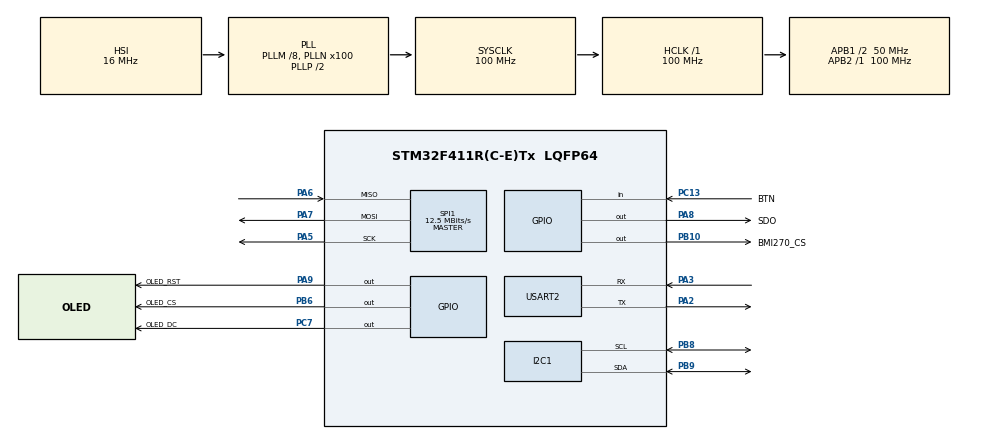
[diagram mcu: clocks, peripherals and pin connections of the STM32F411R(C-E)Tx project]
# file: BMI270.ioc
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Dma.I2C1_RX.1.Direction=DMA_PERIPH_TO_MEMORY
Dma.I2C1_RX.1.FIFOMode=DMA_FIFOMODE_DISABLE
Dma.I2C1_RX.1.Instance=DMA1_Stream0
Dma.I2C1_RX.1.MemDataAlignment=DMA_MDATAALIGN_BYTE
Dma.I2C1_RX.1.MemInc=DMA_MINC_ENABLE
Dma.I2C1_RX.1.Mode=DMA_NORMAL
Dma.I2C1_RX.1.PeriphDataAlignment=DMA_PDATAALIGN_BYTE
Dma.I2C1_RX.1.PeriphInc=DMA_PINC_DISABLE
Dma.I2C1_RX.1.Priority=DMA_PRIORITY_LOW
Dma.I2C1_TX.0.Direction=DMA_MEMORY_TO_PERIPH
Dma.I2C1_TX.0.FIFOMode=DMA_FIFOMODE_DISABLE
Dma.I2C1_TX.0.Instance=DMA1_Stream1
Dma.I2C1_TX.0.MemDataAlignment=DMA_MDATAALIGN_BYTE
Dma.I2C1_TX.0.MemInc=DMA_MINC_ENABLE
Dma.I2C1_TX.0.Mode=DMA_NORMAL
Dma.I2C1_TX.0.PeriphDataAlignment=DMA_PDATAALIGN_BYTE
Dma.I2C1_TX.0.PeriphInc=DMA_PINC_DISABLE
Dma.I2C1_TX.0.Priority=DMA_PRIORITY_LOW
Dma.Request0=I2C1_TX
Dma.Request1=I2C1_RX
I2C1.I2C_Mode=I2C_Fast
Mcu.Family=STM32F4
Mcu.Name=STM32F411R(C-E)Tx
Mcu.Package=LQFP64
NVIC.DMA1_Stream0_IRQn=true\:0\:0\:false\:false\:true\:false\:true\:true
NVIC.DMA1_Stream1_IRQn=true\:0\:0\:false\:false\:true\:false\:true\:true
NVIC.PriorityGroup=NVIC_PRIORITYGROUP_4
NVIC.RTC_WKUP_IRQn=true\:0\:0\:false\:false\:true\:true\:true\:true
PA13.Mode=Serial_Wire
PA13.Signal=SYS_JTMS-SWDIO
PA14.Mode=Serial_Wire
PA14.Signal=SYS_JTCK-SWCLK
PA2.Mode=Asynchronous
PA2.Signal=USART2_TX
PA3.Mode=Asynchronous
PA3.Signal=USART2_RX
PA5.Mode=Full_Duplex_Master
PA5.Signal=SPI1_SCK
PA6.Mode=Full_Duplex_Master
PA6.Signal=SPI1_MISO
PA7.Mode=Full_Duplex_Master
PA7.Signal=SPI1_MOSI
PA8.GPIO_Label=SDO
PA8.Signal=GPIO_Output
PA9.GPIO_Label=OLED_RST
PA9.Signal=GPIO_Output
PB10.GPIO_Label=BMI270_CS
PB10.Signal=GPIO_Output
PB6.GPIO_Label=OLED_CS
PB6.Signal=GPIO_Output
PB8.GPIO_Pu=GPIO_NOPULL
PB8.Mode=I2C
PB8.Signal=I2C1_SCL
PB9.GPIO_Pu=GPIO_NOPULL
PB9.Mode=I2C
PB9.Signal=I2C1_SDA
PC13-ANTI_TAMP.GPIO_Label=BTN
PC13-ANTI_TAMP.GPIO_PuPd=GPIO_PULLUP
PC13-ANTI_TAMP.Signal=GPIO_Input
PC14-OSC32_IN.Mode=LSE-External-Oscillator
PC14-OSC32_IN.Signal=RCC_OSC32_IN
PC15-OSC32_OUT.Mode=LSE-External-Oscillator
PC15-OSC32_OUT.Signal=RCC_OSC32_OUT
PC7.GPIO_Label=OLED_DC
PC7.Signal=GPIO_Output
ProjectManager.HeapSize=0x200
ProjectManager.StackSize=0x400
ProjectManager.TargetToolchain=STM32CubeIDE
RCC.48MHZClocksFreq_Value=50000000
RCC.AHBFreq_Value=100000000
RCC.APB1CLKDivider=RCC_HCLK_DIV2
RCC.APB1Freq_Value=50000000
RCC.APB1TimFreq_Value=100000000
RCC.APB2Freq_Value=100000000
RCC.APB2TimFreq_Value=100000000
RCC.CortexFreq_Value=100000000
RCC.HCLKFreq_Value=100000000
RCC.HSE_VALUE=25000000
RCC.HSI_VALUE=16000000
RCC.PLLM=8
RCC.PLLN=100
RCC.RCC_RTC_Clock_Source=RCC_RTCCLKSOURCE_LSE
RCC.RCC_RTC_Clock_SourceVirtual=RCC_RTCCLKSOURCE_LSE
RCC.SYSCLKFreq_VALUE=100000000
RCC.SYSCLKSource=RCC_SYSCLKSOURCE_PLLCLK
RCC.VCOOutputFreq_Value=200000000
RTC.WakeUpClock=RTC_WAKEUPCLOCK_RTCCLK_DIV16
RTC.WakeUpCounter=0
SPI1.BaudRatePrescaler=SPI_BAUDRATEPRESCALER_8
SPI1.CLKPhase=SPI_PHASE_2EDGE
SPI1.CLKPolarity=SPI_POLARITY_LOW
SPI1.CalculateBaudRate=12.5 MBits/s
SPI1.Direction=SPI_DIRECTION_2LINES
SPI1.Mode=SPI_MODE_MASTER
SPI1.VirtualType=VM_MASTER
USART2.VirtualMode=VM_ASYNC
VP_RTC_VS_RTC_Activate.Mode=RTC_Enabled
VP_RTC_VS_RTC_WakeUp_intern.Mode=WakeUp
VP_TIM5_VS_ClockSourceINT.Mode=Internal
board=custom

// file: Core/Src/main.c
/* USER CODE BEGIN Header */
/**
  ******************************************************************************
  * @file           : main.c
  * @brief          : Main program body
  ******************************************************************************
  * @attention
  *
  * Copyright (c) 2026 STMicroelectronics.
  * All rights reserved.
  *
  * This software is licensed under terms that can be found in the LICENSE file
  * in the root directory of this software component.
  * If no LICENSE file comes with this software, it is provided AS-IS.
  *
  ******************************************************************************
  */
/* USER CODE END Header */
#include "main.h"
#include "dma.h"
#include "i2c.h"
#include "rtc.h"
#include "spi.h"
#include "tim.h"
#include "usart.h"
#include "gpio.h"

/* USER CODE BEGIN Includes */
#include <stdio.h>
/* USER CODE END Includes */

/* USER CODE BEGIN PV */
uint8_t Buffer[25] = {0};
uint8_t temp[50];
uint8_t Space[] = " -- ";
uint8_t NewLine[] = "\r\n";
uint8_t StartMSG[] = "Starting I2C Scanning: \r\n";
uint8_t EndMSG[] = "\r\n ------ Done! ----- \r\n\r\n";
uint8_t i2c_address;

uint8_t bmi270_Config_File[8192] = {
    0xc8, 0x2e, 0x00, 0x2e, 0x80, 0x2e, 0x3d, 0xb1, 0xc8, 0x2e, 0x00, 0x2e, 0x80, 0x2e, 0x91, 0x03, 0x80, 0x2e, 0xbc,
    0xb0, 0x80, 0x2e, 0xa3, 0x03, 0xc8, 0x2e, 0x00, 0x2e, 0x80, 0x2e, 0x00, 0xb0, 0x50, 0x30, 0x21, 0x2e, 0x59, 0xf5,
    0x10, 0x30, 0x21, 0x2e, 0x6a, 0xf5, 0x80, 0x2e, 0x3b, 0x03, 0x00, 0x00, 0x00, 0x00, 0x08, 0x19, 0x01, 0x00, 0x22,
    0x00, 0x75, 0x00, 0x00, 0x10, 0x00, 0x10, 0xd1, 0x00, 0xb3, 0x43, 0x80, 0x2e, 0x00, 0xc1, 0x80, 0x2e, 0x00, 0xc1,
    0x80, 0x2e, 0x00, 0xc1, 0x80, 0x2e, 0x00, 0xc1, 0x80, 0x2e, 0x00, 0xc1, 0x80, 0x2e, 0x00, 0xc1, 0x80, 0x2e, 0x00,
    0xc1, 0x80, 0x2e, 0x00, 0xc1, 0x80, 0x2e, 0x00, 0xc1, 0x80, 0x2e, 0x00, 0xc1, 0x80, 0x2e, 0x00, 0xc1, 0x80, 0x2e,
    0x00, 0xc1, 0x80, 0x2e, 0x00, 0xc1, 0x80, 0x2e, 0x00, 0xc1, 0x80, 0x2e, 0x00, 0xc1, 0x80, 0x2e, 0x00, 0xc1, 0x80,
    0x2e, 0x00, 0xc1, 0x80, 0x2e, 0x00, 0xc1, 0x80, 0x2e, 0x00, 0xc1, 0x80, 0x2e, 0x00, 0xc1, 0x80, 0x2e, 0x00, 0xc1,
    0x80, 0x2e, 0x00, 0xc1, 0x80, 0x2e, 0x00, 0xc1, 0x80, 0x2e, 0x00, 0xc1, 0x80, 0x2e, 0x00, 0xc1, 0x80, 0x2e, 0x00,
    0xc1, 0x80, 0x2e, 0x00, 0xc1, 0x80, 0x2e, 0x00, 0xc1, 0x80, 0x2e, 0x00, 0xc1, 0x80, 0x2e, 0x00, 0xc1, 0x80, 0x2e,
    0x00, 0xc1, 0x80, 0x2e, 0x00, 0xc1, 0x80, 0x2e, 0x00, 0xc1, 0x80, 0x2e, 0x00, 0xc1, 0x80, 0x2e, 0x00, 0xc1, 0x80,
    0x2e, 0x00, 0xc1, 0x80, 0x2e, 0x00, 0xc1, 0x80, 0x2e, 0x00, 0xc1, 0x80, 0x2e, 0x00, 0xc1, 0x80, 0x2e, 0x00, 0xc1,
    0x80, 0x2e, 0x00, 0xc1, 0x80, 0x2e, 0x00, 0xc1, 0xe0, 0x5f, 0x00, 0x00, 0x00, 0x00, 0x01, 0x00, 0x00, 0x00, 0x00,
    0x00, 0x00, 0x00, 0x00, 0x00, 0x00, 0x00, 0x92, 0x00, 0x00, 0x00, 0x00, 0x00, 0x00, 0x00, 0x00, 0x00, 0x00, 0x00,
    0x00, 0x00, 0x00, 0x00, 0x00, 0x00, 0x08, 0x19, 0x00, 0x00, 0x88, 0x00, 0x00, 0x00, 0x00, 0x00, 0x00, 0x00, 0x05,
    0xe0, 0xaa, 0x38, 0x05, 0xe0, 0x90, 0x30, 0xfa, 0x00, 0x96, 0x00, 0x4b, 0x09, 0x11, 0x00, 0x11, 0x00, 0x02, 0x00,
    0x2d, 0x01, 0xd4, 0x7b, 0x3b, 0x01, 0xdb, 0x7a, 0x04, 0x00, 0x3f, 0x7b, 0xcd, 0x6c, 0xc3, 0x04, 0x85, 0x09, 0xc3,
    0x04, 0xec, 0xe6, 0x0c, 0x46, 0x01, 0x00, 0x27, 0x00, 0x19, 0x00, 0x96, 0x00, 0xa0, 0x00, 0x01, 0x00, 0x0c, 0x00,
    0xf0, 0x3c, 0x00, 0x01, 0x01, 0x00, 0x03, 0x00, 0x01, 0x00, 0x0e, 0x00, 0x00, 0x00, 0x32, 0x00, 0x05, 0x00, 0xee,
    0x06, 0x04, 0x00, 0xc8, 0x00, 0x00, 0x00, 0x04, 0x00, 0xa8, 0x05, 0xee, 0x06, 0x00, 0x04, 0xbc, 0x02, 0xb3, 0x00,
    0x85, 0x07, 0x00, 0x00, 0x00, 0x00, 0x00, 0x00, 0x00, 0x00, 0x00, 0x00, 0x00, 0x00, 0x00, 0x00, 0x00, 0x00, 0x00,
    0x00, 0x00, 0x00, 0xb4, 0x00, 0x01, 0x00, 0xb9, 0x00, 0x01, 0x00, 0x98, 0x00, 0x00, 0x00, 0x00, 0x00, 0x00, 0x00,
    0x00, 0x00, 0x01, 0x00, 0x80, 0x00, 0x04, 0x00, 0x00, 0x00, 0x00, 0x00, 0x00, 0x00, 0x00, 0x00, 0x00, 0x00, 0x00,
    0x00, 0x00, 0x00, 0x00, 0x00, 0x00, 0x00, 0x00, 0x00, 0x00, 0x00, 0x00, 0x00, 0x00, 0x00, 0x00, 0x00, 0x00, 0x00,
    0x00, 0x00, 0x00, 0x00, 0x00, 0x00, 0x00, 0x00, 0x00, 0x00, 0x00, 0x00, 0x00, 0x00, 0x00, 0x00, 0x00, 0x00, 0x00,
    0x00, 0x00, 0x00, 0x00, 0x00, 0x00, 0x00, 0x00, 0x00, 0x00, 0x00, 0x00, 0x00, 0x00, 0x00, 0x00, 0x00, 0x00, 0x00,
    0x00, 0x00, 0x00, 0x00, 0x00, 0x00, 0x00, 0x00, 0x00, 0x00, 0x00, 0x00, 0x80, 0x2e, 0x00, 0xc1, 0xfd, 0x2d, 0xde,
    0x00, 0xeb, 0x00, 0xda, 0x00, 0x00, 0x0c, 0xff, 0x0f, 0x00, 0x04, 0xc0, 0x00, 0x5b, 0xf5, 0xc9, 0x01, 0x1e, 0xf2,
    0x80, 0x00, 0x3f, 0xff, 0x19, 0xf4, 0x58, 0xf5, 0x66, 0xf5, 0x64, 0xf5, 0xc0, 0xf1, 0xf0, 0x00, 0xe0, 0x00, 0xcd,
    0x01, 0xd3, 0x01, 0xdb, 0x01, 0xff, 0x7f, 0xff, 0x01, 0xe4, 0x00, 0x74, 0xf7, 0xf3, 0x00, 0xfa, 0x00, 0xff, 0x3f,
    0xca, 0x03, 0x6c, 0x38, 0x56, 0xfe, 0x44, 0xfd, 0xbc, 0x02, 0xf9, 0x06, 0x00, 0xfc, 0x12, 0x02, 0xae, 0x01, 0x58,
    0xfa, 0x9a, 0xfd, 0x77, 0x05, 0xbb, 0x02, 0x96, 0x01, 0x95, 0x01, 0x7f, 0x01, 0x82, 0x01, 0x89, 0x01, 0x87, 0x01,
    0x88, 0x01, 0x8a, 0x01, 0x8c, 0x01, 0x8f, 0x01, 0x8d, 0x01, 0x92, 0x01, 0x91, 0x01, 0xdd, 0x00, 0x9f, 0x01, 0x7e,
    0x01, 0xdb, 0x00, 0xb6, 0x01, 0x70, 0x69, 0x26, 0xd3, 0x9c, 0x07, 0x1f, 0x05, 0x9d, 0x00, 0x00, 0x08, 0xbc, 0x05,
    0x37, 0xfa, 0xa2, 0x01, 0xaa, 0x01, 0xa1, 0x01, 0xa8, 0x01, 0xa0, 0x01, 0xa8, 0x05, 0xb4, 0x01, 0xb4, 0x01, 0xce,
    0x00, 0xd0, 0x00, 0xfc, 0x00, 0xc5, 0x01, 0xff, 0xfb, 0xb1, 0x00, 0x00, 0x38, 0x00, 0x30, 0xfd, 0xf5, 0xfc, 0xf5,
    0xcd, 0x01, 0xa0, 0x00, 0x5f, 0xff, 0x00, 0x40, 0xff, 0x00, 0x00, 0x80, 0x6d, 0x0f, 0xeb, 0x00, 0x7f, 0xff, 0xc2,
    0xf5, 0x68, 0xf7, 0xb3, 0xf1, 0x67, 0x0f, 0x5b, 0x0f, 0x61, 0x0f, 0x80, 0x0f, 0x58, 0xf7, 0x5b, 0xf7, 0x83, 0x0f,
    0x86, 0x00, 0x72, 0x0f, 0x85, 0x0f, 0xc6, 0xf1, 0x7f, 0x0f, 0x6c, 0xf7, 0x00, 0xe0, 0x00, 0xff, 0xd1, 0xf5, 0x87,
    0x0f, 0x8a, 0x0f, 0xff, 0x03, 0xf0, 0x3f, 0x8b, 0x00, 0x8e, 0x00, 0x90, 0x00, 0xb9, 0x00, 0x2d, 0xf5, 0xca, 0xf5,
    0xcb, 0x01, 0x20, 0xf2, 0x00, 0x00, 0x00, 0x00, 0x00, 0x00, 0x00, 0x00, 0x00, 0x00, 0x00, 0x00, 0x00, 0x00, 0x00,
    0x00, 0x00, 0x00, 0x00, 0x00, 0x00, 0x00, 0x00, 0x00, 0x00, 0x00, 0x00, 0x00, 0x00, 0x00, 0x00, 0x00, 0x00, 0x00,
    0x00, 0x00, 0x00, 0x00, 0x00, 0x00, 0x00, 0x00, 0x00, 0x00, 0x00, 0x00, 0x00, 0x00, 0x00, 0x00, 0x00, 0x00, 0x00,
    0x00, 0x00, 0x00, 0x00, 0x00, 0x00, 0x00, 0x00, 0x00, 0x00, 0x00, 0x00, 0x00, 0x00, 0x00, 0x00, 0x00, 0x00, 0x00,
    0x00, 0x00, 0x00, 0x00, 0x00, 0x00, 0x00, 0x00, 0x00, 0x00, 0x00, 0x00, 0x00, 0x00, 0x00, 0x00, 0x00, 0x00, 0x00,
    0x00, 0x00, 0x00, 0x00, 0x00, 0x00, 0x00, 0x00, 0x00, 0x00, 0x00, 0x00, 0x00, 0x00, 0x00, 0x00, 0x00, 0x00, 0x00,
    0x00, 0x00, 0x00, 0x00, 0x00, 0x00, 0x00, 0x00, 0x00, 0x00, 0x00, 0x00, 0x00, 0x00, 0x00, 0x00, 0x00, 0x00, 0x00,
    0x00, 0x00, 0x00, 0x00, 0x00, 0x00, 0x00, 0x00, 0x00, 0x00, 0x00, 0x00, 0x00, 0x00, 0x00, 0x00, 0x00, 0x00, 0x00,
    0x00, 0x00, 0x00, 0x00, 0x00, 0x00, 0x00, 0x00, 0x00, 0x00, 0x00, 0x00, 0x00, 0x00, 0x00, 0x00, 0x00, 0x00, 0x00,
    0x00, 0x00, 0x00, 0x00, 0x00, 0x00, 0x00, 0x00, 0x00, 0x00, 0x00, 0x00, 0x00, 0x00, 0x00, 0x00, 0x00, 0x00, 0x00,
    0x00, 0x00, 0x00, 0x00, 0x00, 0x00, 0x00, 0x00, 0x00, 0x00, 0x00, 0x00, 0x00, 0x00, 0x00, 0x00, 0x00, 0x00, 0x00,
    0x00, 0x00, 0x00, 0x00, 0x00, 0x00, 0x00, 0x00, 0x00, 0x00, 0x00, 0x00, 0x00, 0x00, 0x00, 0x30, 0x50, 0x98, 0x2e,
    0xd7, 0x0e, 0x50, 0x32, 0x98, 0x2e, 0xfa, 0x03, 0x00, 0x30, 0xf0, 0x7f, 0x00, 0x2e, 0x00, 0x2e, 0xd0, 0x2e, 0x00,
    0x2e, 0x01, 0x80, 0x08, 0xa2, 0xfb, 0x2f, 0x98, 0x2e, 0xba, 0x03, 0x21, 0x2e, 0x19, 0x00, 0x01, 0x2e, 0xee, 0x00,
    0x00, 0xb2, 0x07, 0x2f, 0x01, 0x2e, 0x19, 0x00, 0x00, 0xb2, 0x03, 0x2f, 0x01, 0x50, 0x03, 0x52, 0x98, 0x2e, 0x07,
    0xcc, 0x01, 0x2e, 0xdd, 0x00, 0x00, 0xb2, 0x27, 0x2f, 0x05, 0x2e, 0x8a, 0x00, 0x05, 0x52, 0x98, 0x2e, 0xc7, 0xc1,
    0x03, 0x2e, 0xe9, 0x00, 0x40, 0xb2, 0xf0, 0x7f, 0x08, 0x2f, 0x01, 0x2e, 0x19, 0x00, 0x00, 0xb2, 0x04, 0x2f, 0x00,
    0x30, 0x21, 0x2e, 0xe9, 0x00, 0x98, 0x2e, 0xb4, 0xb1, 0x01, 0x2e, 0x18, 0x00, 0x00, 0xb2, 0x10, 0x2f, 0x05, 0x50,
    0x98, 0x2e, 0x4d, 0xc3, 0x05, 0x50, 0x98, 0x2e, 0x5a, 0xc7, 0x98, 0x2e, 0xf9, 0xb4, 0x98, 0x2e, 0x54, 0xb2, 0x98,
    0x2e, 0x67, 0xb6, 0x98, 0x2e, 0x17, 0xb2, 0x10, 0x30, 0x21, 0x2e, 0x77, 0x00, 0x01, 0x2e, 0xef, 0x00, 0x00, 0xb2,
    0x04, 0x2f, 0x98, 0x2e, 0x7a, 0xb7, 0x00, 0x30, 0x21, 0x2e, 0xef, 0x00, 0x01, 0x2e, 0xd4, 0x00, 0x04, 0xae, 0x0b,
    0x2f, 0x01, 0x2e, 0xdd, 0x00, 0x00, 0xb2, 0x07, 0x2f, 0x05, 0x52, 0x98, 0x2e, 0x8e, 0x0e, 0x00, 0xb2, 0x02, 0x2f,
    0x10, 0x30, 0x21, 0x2e, 0x7d, 0x00, 0x01, 0x2e, 0x7d, 0x00, 0x00, 0x90, 0x90, 0x2e, 0xf1, 0x02, 0x01, 0x2e, 0xd7,
    0x00, 0x00, 0xb2, 0x04, 0x2f, 0x98, 0x2e, 0x2f, 0x0e, 0x00, 0x30, 0x21, 0x2e, 0x7b, 0x00, 0x01, 0x2e, 0x7b, 0x00,
    0x00, 0xb2, 0x12, 0x2f, 0x01, 0x2e, 0xd4, 0x00, 0x00, 0x90, 0x02, 0x2f, 0x98, 0x2e, 0x1f, 0x0e, 0x09, 0x2d, 0x98,
    0x2e, 0x81, 0x0d, 0x01, 0x2e, 0xd4, 0x00, 0x04, 0x90, 0x02, 0x2f, 0x50, 0x32, 0x98, 0x2e, 0xfa, 0x03, 0x00, 0x30,
    0x21, 0x2e, 0x7b, 0x00, 0x01, 0x2e, 0x7c, 0x00, 0x00, 0xb2, 0x90, 0x2e, 0x09, 0x03, 0x01, 0x2e, 0x7c, 0x00, 0x01,
    0x31, 0x01, 0x08, 0x00, 0xb2, 0x04, 0x2f, 0x98, 0x2e, 0x47, 0xcb, 0x10, 0x30, 0x21, 0x2e, 0x77, 0x00, 0x81, 0x30,
    0x01, 0x2e, 0x7c, 0x00, 0x01, 0x08, 0x00, 0xb2, 0x61, 0x2f, 0x03, 0x2e, 0x89, 0x00, 0x01, 0x2e, 0xd4, 0x00, 0x98,
    0xbc, 0x98, 0xb8, 0x05, 0xb2, 0x0f, 0x58, 0x23, 0x2f, 0x07, 0x90, 0x09, 0x54, 0x00, 0x30, 0x37, 0x2f, 0x15, 0x41,
    0x04, 0x41, 0xdc, 0xbe, 0x44, 0xbe, 0xdc, 0xba, 0x2c, 0x01, 0x61, 0x00, 0x0f, 0x56, 0x4a, 0x0f, 0x0c, 0x2f, 0xd1,
    0x42, 0x94, 0xb8, 0xc1, 0x42, 0x11, 0x30, 0x05, 0x2e, 0x6a, 0xf7, 0x2c, 0xbd, 0x2f, 0xb9, 0x80, 0xb2, 0x08, 0x22,
    0x98, 0x2e, 0xc3, 0xb7, 0x21, 0x2d, 0x61, 0x30, 0x23, 0x2e, 0xd4, 0x00, 0x98, 0x2e, 0xc3, 0xb7, 0x00, 0x30, 0x21,
    0x2e, 0x5a, 0xf5, 0x18, 0x2d, 0xe1, 0x7f, 0x50, 0x30, 0x98, 0x2e, 0xfa, 0x03, 0x0f, 0x52, 0x07, 0x50, 0x50, 0x42,
    0x70, 0x30, 0x0d, 0x54, 0x42, 0x42, 0x7e, 0x82, 0xe2, 0x6f, 0x80, 0xb2, 0x42, 0x42, 0x05, 0x2f, 0x21, 0x2e, 0xd4,
    0x00, 0x10, 0x30, 0x98, 0x2e, 0xc3, 0xb7, 0x03, 0x2d, 0x60, 0x30, 0x21, 0x2e, 0xd4, 0x00, 0x01, 0x2e, 0xd4, 0x00,
    0x06, 0x90, 0x18, 0x2f, 0x01, 0x2e, 0x76, 0x00, 0x0b, 0x54, 0x07, 0x52, 0xe0, 0x7f, 0x98, 0x2e, 0x7a, 0xc1, 0xe1,
    0x6f, 0x08, 0x1a, 0x40, 0x30, 0x08, 0x2f, 0x21, 0x2e, 0xd4, 0x00, 0x20, 0x30, 0x98, 0x2e, 0xaf, 0xb7, 0x50, 0x32,
    0x98, 0x2e, 0xfa, 0x03, 0x05, 0x2d, 0x98, 0x2e, 0x38, 0x0e, 0x00, 0x30, 0x21, 0x2e, 0xd4, 0x00, 0x00, 0x30, 0x21,
    0x2e, 0x7c, 0x00, 0x18, 0x2d, 0x01, 0x2e, 0xd4, 0x00, 0x03, 0xaa, 0x01, 0x2f, 0x98, 0x2e, 0x45, 0x0e, 0x01, 0x2e,
    0xd4, 0x00, 0x3f, 0x80, 0x03, 0xa2, 0x01, 0x2f, 0x00, 0x2e, 0x02, 0x2d, 0x98, 0x2e, 0x5b, 0x0e, 0x30, 0x30, 0x98,
    0x2e, 0xce, 0xb7, 0x00, 0x30, 0x21, 0x2e, 0x7d, 0x00, 0x50, 0x32, 0x98, 0x2e, 0xfa, 0x03, 0x01, 0x2e, 0x77, 0x00,
    0x00, 0xb2, 0x24, 0x2f, 0x98, 0x2e, 0xf5, 0xcb, 0x03, 0x2e, 0xd5, 0x00, 0x11, 0x54, 0x01, 0x0a, 0xbc, 0x84, 0x83,
    0x86, 0x21, 0x2e, 0xc9, 0x01, 0xe0, 0x40, 0x13, 0x52, 0xc4, 0x40, 0x82, 0x40, 0xa8, 0xb9, 0x52, 0x42, 0x43, 0xbe,
    0x53, 0x42, 0x04, 0x0a, 0x50, 0x42, 0xe1, 0x7f, 0xf0, 0x31, 0x41, 0x40, 0xf2, 0x6f, 0x25, 0xbd, 0x08, 0x08, 0x02,
    0x0a, 0xd0, 0x7f, 0x98, 0x2e, 0xa8, 0xcf, 0x06, 0xbc, 0xd1, 0x6f, 0xe2, 0x6f, 0x08, 0x0a, 0x80, 0x42, 0x98, 0x2e,
    0x58, 0xb7, 0x00, 0x30, 0x21, 0x2e, 0xee, 0x00, 0x21, 0x2e, 0x77, 0x00, 0x21, 0x2e, 0xdd, 0x00, 0x80, 0x2e, 0xf4,
    0x01, 0x1a, 0x24, 0x22, 0x00, 0x80, 0x2e, 0xec, 0x01, 0x10, 0x50, 0xfb, 0x7f, 0x98, 0x2e, 0xf3, 0x03, 0x57, 0x50,
    0xfb, 0x6f, 0x01, 0x30, 0x71, 0x54, 0x11, 0x42, 0x42, 0x0e, 0xfc, 0x2f, 0xc0, 0x2e, 0x01, 0x42, 0xf0, 0x5f, 0x80,
    0x2e, 0x00, 0xc1, 0xfd, 0x2d, 0x01, 0x00, 0x00, 0x00, 0x00, 0x00, 0x00, 0x00, 0x00, 0x00, 0x00, 0x00, 0x9a, 0x01,
    0x34, 0x03, 0x00, 0x00, 0x00, 0x00, 0x00, 0x00, 0x00, 0x00, 0x00, 0x00, 0x00, 0x00, 0x00, 0x00, 0x00, 0x00, 0x00,
    0x00, 0x00, 0x00, 0x00, 0x00, 0x00, 0x00, 0x00, 0x00, 0x00, 0x00, 0x00, 0x00, 0x00, 0x00, 0x00, 0x00, 0x00, 0x00,
    0x00, 0x00, 0x00, 0x00, 0x00, 0x00, 0x00, 0x00, 0x00, 0x00, 0x00, 0x00, 0x00, 0x00, 0x00, 0x00, 0x00, 0x00, 0x00,
    0x00, 0x00, 0x00, 0x00, 0x00, 0x00, 0x00, 0x00, 0x00, 0x00, 0x00, 0x00, 0x00, 0x00, 0x00, 0x00, 0x00, 0x00, 0x00,
    0x00, 0x00, 0x00, 0x00, 0x00, 0x00, 0x00, 0x00, 0x00, 0x00, 0x00, 0x00, 0x00, 0x00, 0x00, 0x00, 0x00, 0x00, 0x00,
    0x00, 0x00, 0x00, 0x00, 0x00, 0x00, 0x00, 0x00, 0x00, 0x00, 0x00, 0x00, 0x00, 0x00, 0x00, 0x00, 0x00, 0x00, 0x00,
    0x00, 0x00, 0x20, 0x50, 0xe7, 0x7f, 0xf6, 0x7f, 0x06, 0x32, 0x0f, 0x2e, 0x61, 0xf5, 0xfe, 0x09, 0xc0, 0xb3, 0x04,
    0x2f, 0x17, 0x30, 0x2f, 0x2e, 0xef, 0x00, 0x2d, 0x2e, 0x61, 0xf5, 0xf6, 0x6f, 0xe7, 0x6f, 0xe0, 0x5f, 0xc8, 0x2e,
    0x20, 0x50, 0xe7, 0x7f, 0xf6, 0x7f, 0x46, 0x30, 0x0f, 0x2e, 0xa4, 0xf1, 0xbe, 0x09, 0x80, 0xb3, 0x06, 0x2f, 0x0d,
    0x2e, 0xd4, 0x00, 0x84, 0xaf, 0x02, 0x2f, 0x16, 0x30, 0x2d, 0x2e, 0x7b, 0x00, 0x86, 0x30, 0x2d, 0x2e, 0x60, 0xf5,
    0xf6, 0x6f, 0xe7, 0x6f, 0xe0, 0x5f, 0xc8, 0x2e, 0x01, 0x2e, 0x77, 0xf7, 0x09, 0xbc, 0x0f, 0xb8, 0x00, 0xb2, 0x10,
    0x50, 0xfb, 0x7f, 0x10, 0x30, 0x0b, 0x2f, 0x03, 0x2e, 0x8a, 0x00, 0x96, 0xbc, 0x9f, 0xb8, 0x40, 0xb2, 0x05, 0x2f,
    0x03, 0x2e, 0x68, 0xf7, 0x9e, 0xbc, 0x9f, 0xb8, 0x40, 0xb2, 0x07, 0x2f, 0x03, 0x2e, 0x7e, 0x00, 0x41, 0x90, 0x01,
    0x2f, 0x98, 0x2e, 0xdc, 0x03, 0x03, 0x2c, 0x00, 0x30, 0x21, 0x2e, 0x7e, 0x00, 0xfb, 0x6f, 0xf0, 0x5f, 0xb8, 0x2e,
    0x20, 0x50, 0xe0, 0x7f, 0xfb, 0x7f, 0x00, 0x2e, 0x27, 0x50, 0x98, 0x2e, 0x3b, 0xc8, 0x29, 0x50, 0x98, 0x2e, 0xa7,
    0xc8, 0x01, 0x50, 0x98, 0x2e, 0x55, 0xcc, 0xe1, 0x6f, 0x2b, 0x50, 0x98, 0x2e, 0xe0, 0xc9, 0xfb, 0x6f, 0x00, 0x30,
    0xe0, 0x5f, 0x21, 0x2e, 0x7e, 0x00, 0xb8, 0x2e, 0x73, 0x50, 0x01, 0x30, 0x57, 0x54, 0x11, 0x42, 0x42, 0x0e, 0xfc,
    0x2f, 0xb8, 0x2e, 0x21, 0x2e, 0x59, 0xf5, 0x10, 0x30, 0xc0, 0x2e, 0x21, 0x2e, 0x4a, 0xf1, 0x90, 0x50, 0xf7, 0x7f,
    0xe6, 0x7f, 0xd5, 0x7f, 0xc4, 0x7f, 0xb3, 0x7f, 0xa1, 0x7f, 0x90, 0x7f, 0x82, 0x7f, 0x7b, 0x7f, 0x98, 0x2e, 0x35,
    0xb7, 0x00, 0xb2, 0x90, 0x2e, 0x97, 0xb0, 0x03, 0x2e, 0x8f, 0x00, 0x07, 0x2e, 0x91, 0x00, 0x05, 0x2e, 0xb1, 0x00,
    0x3f, 0xba, 0x9f, 0xb8, 0x01, 0x2e, 0xb1, 0x00, 0xa3, 0xbd, 0x4c, 0x0a, 0x05, 0x2e, 0xb1, 0x00, 0x04, 0xbe, 0xbf,
    0xb9, 0xcb, 0x0a, 0x4f, 0xba, 0x22, 0xbd, 0x01, 0x2e, 0xb3, 0x00, 0xdc, 0x0a, 0x2f, 0xb9, 0x03, 0x2e, 0xb8, 0x00,
    0x0a, 0xbe, 0x9a, 0x0a, 0xcf, 0xb9, 0x9b, 0xbc, 0x01, 0x2e, 0x97, 0x00, 0x9f, 0xb8, 0x93, 0x0a, 0x0f, 0xbc, 0x91,
    0x0a, 0x0f, 0xb8, 0x90, 0x0a, 0x25, 0x2e, 0x18, 0x00, 0x05, 0x2e, 0xc1, 0xf5, 0x2e, 0xbd, 0x2e, 0xb9, 0x01, 0x2e,
    0x19, 0x00, 0x31, 0x30, 0x8a, 0x04, 0x00, 0x90, 0x07, 0x2f, 0x01, 0x2e, 0xd4, 0x00, 0x04, 0xa2, 0x03, 0x2f, 0x01,
    0x2e, 0x18, 0x00, 0x00, 0xb2, 0x0c, 0x2f, 0x19, 0x50, 0x05, 0x52, 0x98, 0x2e, 0x4d, 0xb7, 0x05, 0x2e, 0x78, 0x00,
    0x80, 0x90, 0x10, 0x30, 0x01, 0x2f, 0x21, 0x2e, 0x78, 0x00, 0x25, 0x2e, 0xdd, 0x00, 0x98, 0x2e, 0x3e, 0xb7, 0x00,
    0xb2, 0x02, 0x30, 0x01, 0x30, 0x04, 0x2f, 0x01, 0x2e, 0x19, 0x00, 0x00, 0xb2, 0x00, 0x2f, 0x21, 0x30, 0x01, 0x2e,
    0xea, 0x00, 0x08, 0x1a, 0x0e, 0x2f, 0x23, 0x2e, 0xea, 0x00, 0x33, 0x30, 0x1b, 0x50, 0x0b, 0x09, 0x01, 0x40, 0x17,
    0x56, 0x46, 0xbe, 0x4b, 0x08, 0x4c, 0x0a, 0x01, 0x42, 0x0a, 0x80, 0x15, 0x52, 0x01, 0x42, 0x00, 0x2e, 0x01, 0x2e,
    0x18, 0x00, 0x00, 0xb2, 0x1f, 0x2f, 0x03, 0x2e, 0xc0, 0xf5, 0xf0, 0x30, 0x48, 0x08, 0x47, 0xaa, 0x74, 0x30, 0x07,
    0x2e, 0x7a, 0x00, 0x61, 0x22, 0x4b, 0x1a, 0x05, 0x2f, 0x07, 0x2e, 0x66, 0xf5, 0xbf, 0xbd, 0xbf, 0xb9, 0xc0, 0x90,
    0x0b, 0x2f, 0x1d, 0x56, 0x2b, 0x30, 0xd2, 0x42, 0xdb, 0x42, 0x01, 0x04, 0xc2, 0x42, 0x04, 0xbd, 0xfe, 0x80, 0x81,
    0x84, 0x23, 0x2e, 0x7a, 0x00, 0x02, 0x42, 0x02, 0x32, 0x25, 0x2e, 0x62, 0xf5, 0x05, 0x2e, 0xd6, 0x00, 0x81, 0x84,
    0x25, 0x2e, 0xd6, 0x00, 0x02, 0x31, 0x25, 0x2e, 0x60, 0xf5, 0x05, 0x2e, 0x8a, 0x00, 0x0b, 0x50, 0x90, 0x08, 0x80,
    0xb2, 0x0b, 0x2f, 0x05, 0x2e, 0xca, 0xf5, 0xf0, 0x3e, 0x90, 0x08, 0x25, 0x2e, 0xca, 0xf5, 0x05, 0x2e, 0x59, 0xf5,
    0xe0, 0x3f, 0x90, 0x08, 0x25, 0x2e, 0x59, 0xf5, 0x90, 0x6f, 0xa1, 0x6f, 0xb3, 0x6f, 0xc4, 0x6f, 0xd5, 0x6f, 0xe6,
    0x6f, 0xf7, 0x6f, 0x7b, 0x6f, 0x82, 0x6f, 0x70, 0x5f, 0xc8, 0x2e, 0xc0, 0x50, 0x90, 0x7f, 0xe5, 0x7f, 0xd4, 0x7f,
    0xc3, 0x7f, 0xb1, 0x7f, 0xa2, 0x7f, 0x87, 0x7f, 0xf6, 0x7f, 0x7b, 0x7f, 0x00, 0x2e, 0x01, 0x2e, 0x60, 0xf5, 0x60,
    0x7f, 0x98, 0x2e, 0x35, 0xb7, 0x02, 0x30, 0x63, 0x6f, 0x15, 0x52, 0x50, 0x7f, 0x62, 0x7f, 0x5a, 0x2c, 0x02, 0x32,
    0x1a, 0x09, 0x00, 0xb3, 0x14, 0x2f, 0x00, 0xb2, 0x03, 0x2f, 0x09, 0x2e, 0x18, 0x00, 0x00, 0x91, 0x0c, 0x2f, 0x43,
    0x7f, 0x98, 0x2e, 0x97, 0xb7, 0x1f, 0x50, 0x02, 0x8a, 0x02, 0x32, 0x04, 0x30, 0x25, 0x2e, 0x64, 0xf5, 0x15, 0x52,
    0x50, 0x6f, 0x43, 0x6f, 0x44, 0x43, 0x25, 0x2e, 0x60, 0xf5, 0xd9, 0x08, 0xc0, 0xb2, 0x36, 0x2f, 0x98, 0x2e, 0x3e,
    0xb7, 0x00, 0xb2, 0x06, 0x2f, 0x01, 0x2e, 0x19, 0x00, 0x00, 0xb2, 0x02, 0x2f, 0x50, 0x6f, 0x00, 0x90, 0x0a, 0x2f,
    0x01, 0x2e, 0x79, 0x00, 0x00, 0x90, 0x19, 0x2f, 0x10, 0x30, 0x21, 0x2e, 0x79, 0x00, 0x00, 0x30, 0x98, 0x2e, 0xdc,
    0x03, 0x13, 0x2d, 0x01, 0x2e, 0xc3, 0xf5, 0x0c, 0xbc, 0x0f, 0xb8, 0x12, 0x30, 0x10, 0x04, 0x03, 0xb0, 0x26, 0x25,
    0x21, 0x50, 0x03, 0x52, 0x98, 0x2e, 0x4d, 0xb7, 0x10, 0x30, 0x21, 0x2e, 0xee, 0x00, 0x02, 0x30, 0x60, 0x7f, 0x25,
    0x2e, 0x79, 0x00, 0x60, 0x6f, 0x00, 0x90, 0x05, 0x2f, 0x00, 0x30, 0x21, 0x2e, 0xea, 0x00, 0x15, 0x50, 0x21, 0x2e,
    0x64, 0xf5, 0x15, 0x52, 0x23, 0x2e, 0x60, 0xf5, 0x02, 0x32, 0x50, 0x6f, 0x00, 0x90, 0x02, 0x2f, 0x03, 0x30, 0x27,
    0x2e, 0x78, 0x00, 0x07, 0x2e, 0x60, 0xf5, 0x1a, 0x09, 0x00, 0x91, 0xa3, 0x2f, 0x19, 0x09, 0x00, 0x91, 0xa0, 0x2f,
    0x90, 0x6f, 0xa2, 0x6f, 0xb1, 0x6f, 0xc3, 0x6f, 0xd4, 0x6f, 0xe5, 0x6f, 0x7b, 0x6f, 0xf6, 0x6f, 0x87, 0x6f, 0x40,
    0x5f, 0xc8, 0x2e, 0xc0, 0x50, 0xe7, 0x7f, 0xf6, 0x7f, 0x26, 0x30, 0x0f, 0x2e, 0x61, 0xf5, 0x2f, 0x2e, 0x7c, 0x00,
    0x0f, 0x2e, 0x7c, 0x00, 0xbe, 0x09, 0xa2, 0x7f, 0x80, 0x7f, 0x80, 0xb3, 0xd5, 0x7f, 0xc4, 0x7f, 0xb3, 0x7f, 0x91,
    0x7f, 0x7b, 0x7f, 0x0b, 0x2f, 0x23, 0x50, 0x1a, 0x25, 0x12, 0x40, 0x42, 0x7f, 0x74, 0x82, 0x12, 0x40, 0x52, 0x7f,
    0x00, 0x2e, 0x00, 0x40, 0x60, 0x7f, 0x98, 0x2e, 0x6a, 0xd6, 0x81, 0x30, 0x01, 0x2e, 0x7c, 0x00, 0x01, 0x08, 0x00,
    0xb2, 0x42, 0x2f, 0x03, 0x2e, 0x89, 0x00, 0x01, 0x2e, 0x89, 0x00, 0x97, 0xbc, 0x06, 0xbc, 0x9f, 0xb8, 0x0f, 0xb8,
    0x00, 0x90, 0x23, 0x2e, 0xd8, 0x00, 0x10, 0x30, 0x01, 0x30, 0x2a, 0x2f, 0x03, 0x2e, 0xd4, 0x00, 0x44, 0xb2, 0x05,
    0x2f, 0x47, 0xb2, 0x00, 0x30, 0x2d, 0x2f, 0x21, 0x2e, 0x7c, 0x00, 0x2b, 0x2d, 0x03, 0x2e, 0xfd, 0xf5, 0x9e, 0xbc,
    0x9f, 0xb8, 0x40, 0x90, 0x14, 0x2f, 0x03, 0x2e, 0xfc, 0xf5, 0x99, 0xbc, 0x9f, 0xb8, 0x40, 0x90, 0x0e, 0x2f, 0x03,
    0x2e, 0x49, 0xf1, 0x25, 0x54, 0x4a, 0x08, 0x40, 0x90, 0x08, 0x2f, 0x98, 0x2e, 0x35, 0xb7, 0x00, 0xb2, 0x10, 0x30,
    0x03, 0x2f, 0x50, 0x30, 0x21, 0x2e, 0xd4, 0x00, 0x10, 0x2d, 0x98, 0x2e, 0xaf, 0xb7, 0x00, 0x30, 0x21, 0x2e, 0x7c,
    0x00, 0x0a, 0x2d, 0x05, 0x2e, 0x69, 0xf7, 0x2d, 0xbd, 0x2f, 0xb9, 0x80, 0xb2, 0x01, 0x2f, 0x21, 0x2e, 0x7d, 0x00,
    0x23, 0x2e, 0x7c, 0x00, 0xe0, 0x31, 0x21, 0x2e, 0x61, 0xf5, 0xf6, 0x6f, 0xe7, 0x6f, 0x80, 0x6f, 0xa2, 0x6f, 0xb3,
    0x6f, 0xc4, 0x6f, 0xd5, 0x6f, 0x7b, 0x6f, 0x91, 0x6f, 0x40, 0x5f, 0xc8, 0x2e, 0x60, 0x51, 0x0a, 0x25, 0x36, 0x88,
    0xf4, 0x7f, 0xeb, 0x7f, 0x00, 0x32, 0x31, 0x52, 0x32, 0x30, 0x13, 0x30, 0x98, 0x2e, 0x15, 0xcb, 0x0a, 0x25, 0x33,
    0x84, 0xd2, 0x7f, 0x43, 0x30, 0x05, 0x50, 0x2d, 0x52, 0x98, 0x2e, 0x95, 0xc1, 0xd2, 0x6f, 0x27, 0x52, 0x98, 0x2e,
    0xd7, 0xc7, 0x2a, 0x25, 0xb0, 0x86, 0xc0, 0x7f, 0xd3, 0x7f, 0xaf, 0x84, 0x29, 0x50, 0xf1, 0x6f, 0x98, 0x2e, 0x4d,
    0xc8, 0x2a, 0x25, 0xae, 0x8a, 0xaa, 0x88, 0xf2, 0x6e, 0x2b, 0x50, 0xc1, 0x6f, 0xd3, 0x6f, 0xf4, 0x7f, 0x98, 0x2e,
    0xb6, 0xc8, 0xe0, 0x6e, 0x00, 0xb2, 0x32, 0x2f, 0x33, 0x54, 0x83, 0x86, 0xf1, 0x6f, 0xc3, 0x7f, 0x04, 0x30, 0x30,
    0x30, 0xf4, 0x7f, 0xd0, 0x7f, 0xb2, 0x7f, 0xe3, 0x30, 0xc5, 0x6f, 0x56, 0x40, 0x45, 0x41, 0x28, 0x08, 0x03, 0x14,
    0x0e, 0xb4, 0x08, 0xbc, 0x82, 0x40, 0x10, 0x0a, 0x2f, 0x54, 0x26, 0x05, 0x91, 0x7f, 0x44, 0x28, 0xa3, 0x7f, 0x98,
    0x2e, 0xd9, 0xc0, 0x08, 0xb9, 0x33, 0x30, 0x53, 0x09, 0xc1, 0x6f, 0xd3, 0x6f, 0xf4, 0x6f, 0x83, 0x17, 0x47, 0x40,
    0x6c, 0x15, 0xb2, 0x6f, 0xbe, 0x09, 0x75, 0x0b, 0x90, 0x42, 0x45, 0x42, 0x51, 0x0e, 0x32, 0xbc, 0x02, 0x89, 0xa1,
    0x6f, 0x7e, 0x86, 0xf4, 0x7f, 0xd0, 0x7f, 0xb2, 0x7f, 0x04, 0x30, 0x91, 0x6f, 0xd6, 0x2f, 0xeb, 0x6f, 0xa0, 0x5e,
    0xb8, 0x2e, 0x03, 0x2e, 0x97, 0x00, 0x1b, 0xbc, 0x60, 0x50, 0x9f, 0xbc, 0x0c, 0xb8, 0xf0, 0x7f, 0x40, 0xb2, 0xeb,
    0x7f, 0x2b, 0x2f, 0x03, 0x2e, 0x7f, 0x00, 0x41, 0x40, 0x01, 0x2e, 0xc8, 0x00, 0x01, 0x1a, 0x11, 0x2f, 0x37, 0x58,
    0x23, 0x2e, 0xc8, 0x00, 0x10, 0x41, 0xa0, 0x7f, 0x38, 0x81, 0x01, 0x41, 0xd0, 0x7f, 0xb1, 0x7f, 0x98, 0x2e, 0x64,
    0xcf, 0xd0, 0x6f, 0x07, 0x80, 0xa1, 0x6f, 0x11, 0x42, 0x00, 0x2e, 0xb1, 0x6f, 0x01, 0x42, 0x11, 0x30, 0x01, 0x2e,
    0xfc, 0x00, 0x00, 0xa8, 0x03, 0x30, 0xcb, 0x22, 0x4a, 0x25, 0x01, 0x2e, 0x7f, 0x00, 0x3c, 0x89, 0x35, 0x52, 0x05,
    0x54, 0x98, 0x2e, 0xc4, 0xce, 0xc1, 0x6f, 0xf0, 0x6f, 0x98, 0x2e, 0x95, 0xcf, 0x04, 0x2d, 0x01, 0x30, 0xf0, 0x6f,
    0x98, 0x2e, 0x95, 0xcf, 0xeb, 0x6f, 0xa0, 0x5f, 0xb8, 0x2e, 0x03, 0x2e, 0xb3, 0x00, 0x02, 0x32, 0xf0, 0x30, 0x03,
    0x31, 0x30, 0x50, 0x8a, 0x08, 0x08, 0x08, 0xcb, 0x08, 0xe0, 0x7f, 0x80, 0xb2, 0xf3, 0x7f, 0xdb, 0x7f, 0x25, 0x2f,
    0x03, 0x2e, 0xca, 0x00, 0x41, 0x90, 0x04, 0x2f, 0x01, 0x30, 0x23, 0x2e, 0xca, 0x00, 0x98, 0x2e, 0x3f, 0x03, 0xc0,
    0xb2, 0x05, 0x2f, 0x03, 0x2e, 0xda, 0x00, 0x00, 0x30, 0x41, 0x04, 0x23, 0x2e, 0xda, 0x00, 0x98, 0x2e, 0x92, 0xb2,
    0x10, 0x25, 0xf0, 0x6f, 0x00, 0xb2, 0x05, 0x2f, 0x01, 0x2e, 0xda, 0x00, 0x02, 0x30, 0x10, 0x04, 0x21, 0x2e, 0xda,
    0x00, 0x40, 0xb2, 0x01, 0x2f, 0x23, 0x2e, 0xc8, 0x01, 0xdb, 0x6f, 0xe0, 0x6f, 0xd0, 0x5f, 0x80, 0x2e, 0x95, 0xcf,
    0x01, 0x30, 0xe0, 0x6f, 0x98, 0x2e, 0x95, 0xcf, 0x11, 0x30, 0x23, 0x2e, 0xca, 0x00, 0xdb, 0x6f, 0xd0, 0x5f, 0xb8,
    0x2e, 0xd0, 0x50, 0x0a, 0x25, 0x33, 0x84, 0x55, 0x50, 0xd2, 0x7f, 0xe2, 0x7f, 0x03, 0x8c, 0xc0, 0x7f, 0xbb, 0x7f,
    0x00, 0x30, 0x05, 0x5a, 0x39, 0x54, 0x51, 0x41, 0xa5, 0x7f, 0x96, 0x7f, 0x80, 0x7f, 0x98, 0x2e, 0xd9, 0xc0, 0x05,
    0x30, 0xf5, 0x7f, 0x20, 0x25, 0x91, 0x6f, 0x3b, 0x58, 0x3d, 0x5c, 0x3b, 0x56, 0x98, 0x2e, 0x67, 0xcc, 0xc1, 0x6f,
    0xd5, 0x6f, 0x52, 0x40, 0x50, 0x43, 0xc1, 0x7f, 0xd5, 0x7f, 0x10, 0x25, 0x98, 0x2e, 0xfe, 0xc9, 0x10, 0x25, 0x98,
    0x2e, 0x74, 0xc0, 0x86, 0x6f, 0x30, 0x28, 0x92, 0x6f, 0x82, 0x8c, 0xa5, 0x6f, 0x6f, 0x52, 0x69, 0x0e, 0x39, 0x54,
    0xdb, 0x2f, 0x19, 0xa0, 0x15, 0x30, 0x03, 0x2f, 0x00, 0x30, 0x21, 0x2e, 0x81, 0x01, 0x0a, 0x2d, 0x01, 0x2e, 0x81,
    0x01, 0x05, 0x28, 0x42, 0x36, 0x21, 0x2e, 0x81, 0x01, 0x02, 0x0e, 0x01, 0x2f, 0x98, 0x2e, 0xf3, 0x03, 0x57, 0x50,
    0x12, 0x30, 0x01, 0x40, 0x98, 0x2e, 0xfe, 0xc9, 0x51, 0x6f, 0x0b, 0x5c, 0x8e, 0x0e, 0x3b, 0x6f, 0x57, 0x58, 0x02,
    0x30, 0x21, 0x2e, 0x95, 0x01, 0x45, 0x6f, 0x2a, 0x8d, 0xd2, 0x7f, 0xcb, 0x7f, 0x13, 0x2f, 0x02, 0x30, 0x3f, 0x50,
    0xd2, 0x7f, 0xa8, 0x0e, 0x0e, 0x2f, 0xc0, 0x6f, 0x53, 0x54, 0x02, 0x00, 0x51, 0x54, 0x42, 0x0e, 0x10, 0x30, 0x59,
    0x52, 0x02, 0x30, 0x01, 0x2f, 0x00, 0x2e, 0x03, 0x2d, 0x50, 0x42, 0x42, 0x42, 0x12, 0x30, 0xd2, 0x7f, 0x80, 0xb2,
    0x03, 0x2f, 0x00, 0x30, 0x21, 0x2e, 0x80, 0x01, 0x12, 0x2d, 0x01, 0x2e, 0xc9, 0x00, 0x02, 0x80, 0x05, 0x2e, 0x80,
    0x01, 0x11, 0x30, 0x91, 0x28, 0x00, 0x40, 0x25, 0x2e, 0x80, 0x01, 0x10, 0x0e, 0x05, 0x2f, 0x01, 0x2e, 0x7f, 0x01,
    0x01, 0x90, 0x01, 0x2f, 0x98, 0x2e, 0xf3, 0x03, 0x00, 0x2e, 0xa0, 0x41, 0x01, 0x90, 0xa6, 0x7f, 0x90, 0x2e, 0xe3,
    0xb4, 0x01, 0x2e, 0x95, 0x01, 0x00, 0xa8, 0x90, 0x2e, 0xe3, 0xb4, 0x5b, 0x54, 0x95, 0x80, 0x82, 0x40, 0x80, 0xb2,
    0x02, 0x40, 0x2d, 0x8c, 0x3f, 0x52, 0x96, 0x7f, 0x90, 0x2e, 0xc2, 0xb3, 0x29, 0x0e, 0x76, 0x2f, 0x01, 0x2e, 0xc9,
    0x00, 0x00, 0x40, 0x81, 0x28, 0x45, 0x52, 0xb3, 0x30, 0x98, 0x2e, 0x0f, 0xca, 0x5d, 0x54, 0x80, 0x7f, 0x00, 0x2e,
    0xa1, 0x40, 0x72, 0x7f, 0x82, 0x80, 0x82, 0x40, 0x60, 0x7f, 0x98, 0x2e, 0xfe, 0xc9, 0x10, 0x25, 0x98, 0x2e, 0x74,
    0xc0, 0x62, 0x6f, 0x05, 0x30, 0x87, 0x40, 0xc0, 0x91, 0x04, 0x30, 0x05, 0x2f, 0x05, 0x2e, 0x83, 0x01, 0x80, 0xb2,
    0x14, 0x30, 0x00, 0x2f, 0x04, 0x30, 0x05, 0x2e, 0xc9, 0x00, 0x73, 0x6f, 0x81, 0x40, 0xe2, 0x40, 0x69, 0x04, 0x11,
    0x0f, 0xe1, 0x40, 0x16, 0x30, 0xfe, 0x29, 0xcb, 0x40, 0x02, 0x2f, 0x83, 0x6f, 0x83, 0x0f, 0x22, 0x2f, 0x47, 0x56,
    0x13, 0x0f, 0x12, 0x30, 0x77, 0x2f, 0x49, 0x54, 0x42, 0x0e, 0x12, 0x30, 0x73, 0x2f, 0x00, 0x91, 0x0a, 0x2f, 0x01,
    0x2e, 0x8b, 0x01, 0x19, 0xa8, 0x02, 0x30, 0x6c, 0x2f, 0x63, 0x50, 0x00, 0x2e, 0x17, 0x42, 0x05, 0x42, 0x68, 0x2c,
    0x12, 0x30, 0x0b, 0x25, 0x08, 0x0f, 0x50, 0x30, 0x02, 0x2f, 0x21, 0x2e, 0x83, 0x01, 0x03, 0x2d, 0x40, 0x30, 0x21,
    0x2e, 0x83, 0x01, 0x2b, 0x2e, 0x85, 0x01, 0x5a, 0x2c, 0x12, 0x30, 0x00, 0x91, 0x2b, 0x25, 0x04, 0x2f, 0x63, 0x50,
    0x02, 0x30, 0x17, 0x42, 0x17, 0x2c, 0x02, 0x42, 0x98, 0x2e, 0xfe, 0xc9, 0x10, 0x25, 0x98, 0x2e, 0x74, 0xc0, 0x05,
    0x2e, 0xc9, 0x00, 0x81, 0x84, 0x5b, 0x30, 0x82, 0x40, 0x37, 0x2e, 0x83, 0x01, 0x02, 0x0e, 0x07, 0x2f, 0x5f, 0x52,
    0x40, 0x30, 0x62, 0x40, 0x41, 0x40, 0x91, 0x0e, 0x01, 0x2f, 0x21, 0x2e, 0x83, 0x01, 0x05, 0x30, 0x2b, 0x2e, 0x85,
    0x01, 0x12, 0x30, 0x36, 0x2c, 0x16, 0x30, 0x15, 0x25, 0x81, 0x7f, 0x98, 0x2e, 0xfe, 0xc9, 0x10, 0x25, 0x98, 0x2e,
    0x74, 0xc0, 0x19, 0xa2, 0x16, 0x30, 0x15, 0x2f, 0x05, 0x2e, 0x97, 0x01, 0x80, 0x6f, 0x82, 0x0e, 0x05, 0x2f, 0x01,
    0x2e, 0x86, 0x01, 0x06, 0x28, 0x21, 0x2e, 0x86, 0x01, 0x0b, 0x2d, 0x03, 0x2e, 0x87, 0x01, 0x5f, 0x54, 0x4e, 0x28,
    0x91, 0x42, 0x00, 0x2e, 0x82, 0x40, 0x90, 0x0e, 0x01, 0x2f, 0x21, 0x2e, 0x88, 0x01, 0x02, 0x30, 0x13, 0x2c, 0x05,
    0x30, 0xc0, 0x6f, 0x08, 0x1c, 0xa8, 0x0f, 0x16, 0x30, 0x05, 0x30, 0x5b, 0x50, 0x09, 0x2f, 0x02, 0x80, 0x2d, 0x2e,
    0x82, 0x01, 0x05, 0x42, 0x05, 0x80, 0x00, 0x2e, 0x02, 0x42, 0x3e, 0x80, 0x00, 0x2e, 0x06, 0x42, 0x02, 0x30, 0x90,
    0x6f, 0x3e, 0x88, 0x01, 0x40, 0x04, 0x41, 0x4c, 0x28, 0x01, 0x42, 0x07, 0x80, 0x10, 0x25, 0x24, 0x40, 0x00, 0x40,
    0x00, 0xa8, 0xf5, 0x22, 0x23, 0x29, 0x44, 0x42, 0x7a, 0x82, 0x7e, 0x88, 0x43, 0x40, 0x04, 0x41, 0x00, 0xab, 0xf5,
    0x23, 0xdf, 0x28, 0x43, 0x42, 0xd9, 0xa0, 0x14, 0x2f, 0x00, 0x90, 0x02, 0x2f, 0xd2, 0x6f, 0x81, 0xb2, 0x05, 0x2f,
    0x63, 0x54, 0x06, 0x28, 0x90, 0x42, 0x85, 0x42, 0x09, 0x2c, 0x02, 0x30, 0x5b, 0x50, 0x03, 0x80, 0x29, 0x2e, 0x7e,
    0x01, 0x2b, 0x2e, 0x82, 0x01, 0x05, 0x42, 0x12, 0x30, 0x2b, 0x2e, 0x83, 0x01, 0x45, 0x82, 0x00, 0x2e, 0x40, 0x40,
    0x7a, 0x82, 0x02, 0xa0, 0x08, 0x2f, 0x63, 0x50, 0x3b, 0x30, 0x15, 0x42, 0x05, 0x42, 0x37, 0x80, 0x37, 0x2e, 0x7e,
    0x01, 0x05, 0x42, 0x12, 0x30, 0x01, 0x2e, 0xc9, 0x00, 0x02, 0x8c, 0x40, 0x40, 0x84, 0x41, 0x7a, 0x8c, 0x04, 0x0f,
    0x03, 0x2f, 0x01, 0x2e, 0x8b, 0x01, 0x19, 0xa4, 0x04, 0x2f, 0x2b, 0x2e, 0x82, 0x01, 0x98, 0x2e, 0xf3, 0x03, 0x12,
    0x30, 0x81, 0x90, 0x61, 0x52, 0x08, 0x2f, 0x65, 0x42, 0x65, 0x42, 0x43, 0x80, 0x39, 0x84, 0x82, 0x88, 0x05, 0x42,
    0x45, 0x42, 0x85, 0x42, 0x05, 0x43, 0x00, 0x2e, 0x80, 0x41, 0x00, 0x90, 0x90, 0x2e, 0xe1, 0xb4, 0x65, 0x54, 0xc1,
    0x6f, 0x80, 0x40, 0x00, 0xb2, 0x43, 0x58, 0x69, 0x50, 0x44, 0x2f, 0x55, 0x5c, 0xb7, 0x87, 0x8c, 0x0f, 0x0d, 0x2e,
    0x96, 0x01, 0xc4, 0x40, 0x36, 0x2f, 0x41, 0x56, 0x8b, 0x0e, 0x2a, 0x2f, 0x0b, 0x52, 0xa1, 0x0e, 0x0a, 0x2f, 0x05,
    0x2e, 0x8f, 0x01, 0x14, 0x25, 0x98, 0x2e, 0xfe, 0xc9, 0x4b, 0x54, 0x02, 0x0f, 0x69, 0x50, 0x05, 0x30, 0x65, 0x54,
    0x15, 0x2f, 0x03, 0x2e, 0x8e, 0x01, 0x4d, 0x5c, 0x8e, 0x0f, 0x3a, 0x2f, 0x05, 0x2e, 0x8f, 0x01, 0x98, 0x2e, 0xfe,
    0xc9, 0x4f, 0x54, 0x82, 0x0f, 0x05, 0x30, 0x69, 0x50, 0x65, 0x54, 0x30, 0x2f, 0x6d, 0x52, 0x15, 0x30, 0x42, 0x8c,
    0x45, 0x42, 0x04, 0x30, 0x2b, 0x2c, 0x84, 0x43, 0x6b, 0x52, 0x42, 0x8c, 0x00, 0x2e, 0x85, 0x43, 0x15, 0x30, 0x24,
    0x2c, 0x45, 0x42, 0x8e, 0x0f, 0x20, 0x2f, 0x0d, 0x2e, 0x8e, 0x01, 0xb1, 0x0e, 0x1c, 0x2f, 0x23, 0x2e, 0x8e, 0x01,
    0x1a, 0x2d, 0x0e, 0x0e, 0x17, 0x2f, 0xa1, 0x0f, 0x15, 0x2f, 0x23, 0x2e, 0x8d, 0x01, 0x13, 0x2d, 0x98, 0x2e, 0x74,
    0xc0, 0x43, 0x54, 0xc2, 0x0e, 0x0a, 0x2f, 0x65, 0x50, 0x04, 0x80, 0x0b, 0x30, 0x06, 0x82, 0x0b, 0x42, 0x79, 0x80,
    0x41, 0x40, 0x12, 0x30, 0x25, 0x2e, 0x8c, 0x01, 0x01, 0x42, 0x05, 0x30, 0x69, 0x50, 0x65, 0x54, 0x84, 0x82, 0x43,
    0x84, 0xbe, 0x8c, 0x84, 0x40, 0x86, 0x41, 0x26, 0x29, 0x94, 0x42, 0xbe, 0x8e, 0xd5, 0x7f, 0x19, 0xa1, 0x43, 0x40,
    0x0b, 0x2e, 0x8c, 0x01, 0x84, 0x40, 0xc7, 0x41, 0x5d, 0x29, 0x27, 0x29, 0x45, 0x42, 0x84, 0x42, 0xc2, 0x7f, 0x01,
    0x2f, 0xc0, 0xb3, 0x1d, 0x2f, 0x05, 0x2e, 0x94, 0x01, 0x99, 0xa0, 0x01, 0x2f, 0x80, 0xb3, 0x13, 0x2f, 0x80, 0xb3,
    0x18, 0x2f, 0xc0, 0xb3, 0x16, 0x2f, 0x12, 0x40, 0x01, 0x40, 0x92, 0x7f, 0x98, 0x2e, 0x74, 0xc0, 0x92, 0x6f, 0x10,
    0x0f, 0x20, 0x30, 0x03, 0x2f, 0x10, 0x30, 0x21, 0x2e, 0x7e, 0x01, 0x0a, 0x2d, 0x21, 0x2e, 0x7e, 0x01, 0x07, 0x2d,
    0x20, 0x30, 0x21, 0x2e, 0x7e, 0x01, 0x03, 0x2d, 0x10, 0x30, 0x21, 0x2e, 0x7e, 0x01, 0xc2, 0x6f, 0x01, 0x2e, 0xc9,
    0x00, 0xbc, 0x84, 0x02, 0x80, 0x82, 0x40, 0x00, 0x40, 0x90, 0x0e, 0xd5, 0x6f, 0x02, 0x2f, 0x15, 0x30, 0x98, 0x2e,
    0xf3, 0x03, 0x41, 0x91, 0x05, 0x30, 0x07, 0x2f, 0x67, 0x50, 0x3d, 0x80, 0x2b, 0x2e, 0x8f, 0x01, 0x05, 0x42, 0x04,
    0x80, 0x00, 0x2e, 0x05, 0x42, 0x02, 0x2c, 0x00, 0x30, 0x00, 0x30, 0xa2, 0x6f, 0x98, 0x8a, 0x86, 0x40, 0x80, 0xa7,
    0x05, 0x2f, 0x98, 0x2e, 0xf3, 0x03, 0xc0, 0x30, 0x21, 0x2e, 0x95, 0x01, 0x06, 0x25, 0x1a, 0x25, 0xe2, 0x6f, 0x76,
    0x82, 0x96, 0x40, 0x56, 0x43, 0x51, 0x0e, 0xfb, 0x2f, 0xbb, 0x6f, 0x30, 0x5f, 0xb8, 0x2e, 0x01, 0x2e, 0xb8, 0x00,
    0x01, 0x31, 0x41, 0x08, 0x40, 0xb2, 0x20, 0x50, 0xf2, 0x30, 0x02, 0x08, 0xfb, 0x7f, 0x01, 0x30, 0x10, 0x2f, 0x05,
    0x2e, 0xcc, 0x00, 0x81, 0x90, 0xe0, 0x7f, 0x03, 0x2f, 0x23, 0x2e, 0xcc, 0x00, 0x98, 0x2e, 0x55, 0xb6, 0x98, 0x2e,
    0x1d, 0xb5, 0x10, 0x25, 0xfb, 0x6f, 0xe0, 0x6f, 0xe0, 0x5f, 0x80, 0x2e, 0x95, 0xcf, 0x98, 0x2e, 0x95, 0xcf, 0x10,
    0x30, 0x21, 0x2e, 0xcc, 0x00, 0xfb, 0x6f, 0xe0, 0x5f, 0xb8, 0x2e, 0x00, 0x51, 0x05, 0x58, 0xeb, 0x7f, 0x2a, 0x25,
    0x89, 0x52, 0x6f, 0x5a, 0x89, 0x50, 0x13, 0x41, 0x06, 0x40, 0xb3, 0x01, 0x16, 0x42, 0xcb, 0x16, 0x06, 0x40, 0xf3,
    0x02, 0x13, 0x42, 0x65, 0x0e, 0xf5, 0x2f, 0x05, 0x40, 0x14, 0x30, 0x2c, 0x29, 0x04, 0x42, 0x08, 0xa1, 0x00, 0x30,
    0x90, 0x2e, 0x52, 0xb6, 0xb3, 0x88, 0xb0, 0x8a, 0xb6, 0x84, 0xa4, 0x7f, 0xc4, 0x7f, 0xb5, 0x7f, 0xd5, 0x7f, 0x92,
    0x7f, 0x73, 0x30, 0x04, 0x30, 0x55, 0x40, 0x42, 0x40, 0x8a, 0x17, 0xf3, 0x08, 0x6b, 0x01, 0x90, 0x02, 0x53, 0xb8,
    0x4b, 0x82, 0xad, 0xbe, 0x71, 0x7f, 0x45, 0x0a, 0x09, 0x54, 0x84, 0x7f, 0x98, 0x2e, 0xd9, 0xc0, 0xa3, 0x6f, 0x7b,
    0x54, 0xd0, 0x42, 0xa3, 0x7f, 0xf2, 0x7f, 0x60, 0x7f, 0x20, 0x25, 0x71, 0x6f, 0x75, 0x5a, 0x77, 0x58, 0x79, 0x5c,
    0x75, 0x56, 0x98, 0x2e, 0x67, 0xcc, 0xb1, 0x6f, 0x62, 0x6f, 0x50, 0x42, 0xb1, 0x7f, 0xb3, 0x30, 0x10, 0x25, 0x98,
    0x2e, 0x0f, 0xca, 0x84, 0x6f, 0x20, 0x29, 0x71, 0x6f, 0x92, 0x6f, 0xa5, 0x6f, 0x76, 0x82, 0x6a, 0x0e, 0x73, 0x30,
    0x00, 0x30, 0xd0, 0x2f, 0xd2, 0x6f, 0xd1, 0x7f, 0xb4, 0x7f, 0x98, 0x2e, 0x2b, 0xb7, 0x15, 0xbd, 0x0b, 0xb8, 0x02,
    0x0a, 0xc2, 0x6f, 0xc0, 0x7f, 0x98, 0x2e, 0x2b, 0xb7, 0x15, 0xbd, 0x0b, 0xb8, 0x42, 0x0a, 0xc0, 0x6f, 0x08, 0x17,
    0x41, 0x18, 0x89, 0x16, 0xe1, 0x18, 0xd0, 0x18, 0xa1, 0x7f, 0x27, 0x25, 0x16, 0x25, 0x98, 0x2e, 0x79, 0xc0, 0x8b,
    0x54, 0x90, 0x7f, 0xb3, 0x30, 0x82, 0x40, 0x80, 0x90, 0x0d, 0x2f, 0x7d, 0x52, 0x92, 0x6f, 0x98, 0x2e, 0x0f, 0xca,
    0xb2, 0x6f, 0x90, 0x0e, 0x06, 0x2f, 0x8b, 0x50, 0x14, 0x30, 0x42, 0x6f, 0x51, 0x6f, 0x14, 0x42, 0x12, 0x42, 0x01,
    0x42, 0x00, 0x2e, 0x31, 0x6f, 0x98, 0x2e, 0x74, 0xc0, 0x41, 0x6f, 0x80, 0x7f, 0x98, 0x2e, 0x74, 0xc0, 0x82, 0x6f,
    0x10, 0x04, 0x43, 0x52, 0x01, 0x0f, 0x05, 0x2e, 0xcb, 0x00, 0x00, 0x30, 0x04, 0x30, 0x21, 0x2f, 0x51, 0x6f, 0x43,
    0x58, 0x8c, 0x0e, 0x04, 0x30, 0x1c, 0x2f, 0x85, 0x88, 0x41, 0x6f, 0x04, 0x41, 0x8c, 0x0f, 0x04, 0x30, 0x16, 0x2f,
    0x84, 0x88, 0x00, 0x2e, 0x04, 0x41, 0x04, 0x05, 0x8c, 0x0e, 0x04, 0x30, 0x0f, 0x2f, 0x82, 0x88, 0x31, 0x6f, 0x04,
    0x41, 0x04, 0x05, 0x8c, 0x0e, 0x04, 0x30, 0x08, 0x2f, 0x83, 0x88, 0x00, 0x2e, 0x04, 0x41, 0x8c, 0x0f, 0x04, 0x30,
    0x02, 0x2f, 0x21, 0x2e, 0xad, 0x01, 0x14, 0x30, 0x00, 0x91, 0x14, 0x2f, 0x03, 0x2e, 0xa1, 0x01, 0x41, 0x90, 0x0e,
    0x2f, 0x03, 0x2e, 0xad, 0x01, 0x14, 0x30, 0x4c, 0x28, 0x23, 0x2e, 0xad, 0x01, 0x46, 0xa0, 0x06, 0x2f, 0x81, 0x84,
    0x8d, 0x52, 0x48, 0x82, 0x82, 0x40, 0x21, 0x2e, 0xa1, 0x01, 0x42, 0x42, 0x5c, 0x2c, 0x02, 0x30, 0x05, 0x2e, 0xaa,
    0x01, 0x80, 0xb2, 0x02, 0x30, 0x55, 0x2f, 0x03, 0x2e, 0xa9, 0x01, 0x92, 0x6f, 0xb3, 0x30, 0x98, 0x2e, 0x0f, 0xca,
    0xb2, 0x6f, 0x90, 0x0f, 0x00, 0x30, 0x02, 0x30, 0x4a, 0x2f, 0xa2, 0x6f, 0x87, 0x52, 0x91, 0x00, 0x85, 0x52, 0x51,
    0x0e, 0x02, 0x2f, 0x00, 0x2e, 0x43, 0x2c, 0x02, 0x30, 0xc2, 0x6f, 0x7f, 0x52, 0x91, 0x0e, 0x02, 0x30, 0x3c, 0x2f,
    0x51, 0x6f, 0x81, 0x54, 0x98, 0x2e, 0xfe, 0xc9, 0x10, 0x25, 0xb3, 0x30, 0x21, 0x25, 0x98, 0x2e, 0x0f, 0xca, 0x32,
    0x6f, 0xc0, 0x7f, 0xb3, 0x30, 0x12, 0x25, 0x98, 0x2e, 0x0f, 0xca, 0x42, 0x6f, 0xb0, 0x7f, 0xb3, 0x30, 0x12, 0x25,
    0x98, 0x2e, 0x0f, 0xca, 0xb2, 0x6f, 0x90, 0x28, 0x83, 0x52, 0x98, 0x2e, 0xfe, 0xc9, 0xc2, 0x6f, 0x90, 0x0f, 0x00,
    0x30, 0x02, 0x30, 0x1d, 0x2f, 0x05, 0x2e, 0xa1, 0x01, 0x80, 0xb2, 0x12, 0x30, 0x0f, 0x2f, 0x42, 0x6f, 0x03, 0x2e,
    0xab, 0x01, 0x91, 0x0e, 0x02, 0x30, 0x12, 0x2f, 0x52, 0x6f, 0x03, 0x2e, 0xac, 0x01, 0x91, 0x0f, 0x02, 0x30, 0x0c,
    0x2f, 0x21, 0x2e, 0xaa, 0x01, 0x0a, 0x2c, 0x12, 0x30, 0x03, 0x2e, 0xcb, 0x00, 0x8d, 0x58, 0x08, 0x89, 0x41, 0x40,
    0x11, 0x43, 0x00, 0x43, 0x25, 0x2e, 0xa1, 0x01, 0xd4, 0x6f, 0x8f, 0x52, 0x00, 0x43, 0x3a, 0x89, 0x00, 0x2e, 0x10,
    0x43, 0x10, 0x43, 0x61, 0x0e, 0xfb, 0x2f, 0x03, 0x2e, 0xa0, 0x01, 0x11, 0x1a, 0x02, 0x2f, 0x02, 0x25, 0x21, 0x2e,
    0xa0, 0x01, 0xeb, 0x6f, 0x00, 0x5f, 0xb8, 0x2e, 0x91, 0x52, 0x10, 0x30, 0x02, 0x30, 0x95, 0x56, 0x52, 0x42, 0x4b,
    0x0e, 0xfc, 0x2f, 0x8d, 0x54, 0x88, 0x82, 0x93, 0x56, 0x80, 0x42, 0x53, 0x42, 0x40, 0x42, 0x42, 0x86, 0x83, 0x54,
    0xc0, 0x2e, 0xc2, 0x42, 0x00, 0x2e, 0xa3, 0x52, 0x00, 0x51, 0x52, 0x40, 0x47, 0x40, 0x1a, 0x25, 0x01, 0x2e, 0x97,
    0x00, 0x8f, 0xbe, 0x72, 0x86, 0xfb, 0x7f, 0x0b, 0x30, 0x7c, 0xbf, 0xa5, 0x50, 0x10, 0x08, 0xdf, 0xba, 0x70, 0x88,
    0xf8, 0xbf, 0xcb, 0x42, 0xd3, 0x7f, 0x6c, 0xbb, 0xfc, 0xbb, 0xc5, 0x0a, 0x90, 0x7f, 0x1b, 0x7f, 0x0b, 0x43, 0xc0,
    0xb2, 0xe5, 0x7f, 0xb7, 0x7f, 0xa6, 0x7f, 0xc4, 0x7f, 0x90, 0x2e, 0x1c, 0xb7, 0x07, 0x2e, 0xd2, 0x00, 0xc0, 0xb2,
    0x0b, 0x2f, 0x97, 0x52, 0x01, 0x2e, 0xcd, 0x00, 0x82, 0x7f, 0x98, 0x2e, 0xbb, 0xcc, 0x0b, 0x30, 0x37, 0x2e, 0xd2,
    0x00, 0x82, 0x6f, 0x90, 0x6f, 0x1a, 0x25, 0x00, 0xb2, 0x8b, 0x7f, 0x14, 0x2f, 0xa6, 0xbd, 0x25, 0xbd, 0xb6, 0xb9,
    0x2f, 0xb9, 0x80, 0xb2, 0xd4, 0xb0, 0x0c, 0x2f, 0x99, 0x54, 0x9b, 0x56, 0x0b, 0x30, 0x0b, 0x2e, 0xb1, 0x00, 0xa1,
    0x58, 0x9b, 0x42, 0xdb, 0x42, 0x6c, 0x09, 0x2b, 0x2e, 0xb1, 0x00, 0x8b, 0x42, 0xcb, 0x42, 0x86, 0x7f, 0x73, 0x84,
    0xa7, 0x56, 0xc3, 0x08, 0x39, 0x52, 0x05, 0x50, 0x72, 0x7f, 0x63, 0x7f, 0x98, 0x2e, 0xc2, 0xc0, 0xe1, 0x6f, 0x62,
    0x6f, 0xd1, 0x0a, 0x01, 0x2e, 0xcd, 0x00, 0xd5, 0x6f, 0xc4, 0x6f, 0x72, 0x6f, 0x97, 0x52, 0x9d, 0x5c, 0x98, 0x2e,
    0x06, 0xcd, 0x23, 0x6f, 0x90, 0x6f, 0x99, 0x52, 0xc0, 0xb2, 0x04, 0xbd, 0x54, 0x40, 0xaf, 0xb9, 0x45, 0x40, 0xe1,
    0x7f, 0x02, 0x30, 0x06, 0x2f, 0xc0, 0xb2, 0x02, 0x30, 0x03, 0x2f, 0x9b, 0x5c, 0x12, 0x30, 0x94, 0x43, 0x85, 0x43,
    0x03, 0xbf, 0x6f, 0xbb, 0x80, 0xb3, 0x20, 0x2f, 0x06, 0x6f, 0x26, 0x01, 0x16, 0x6f, 0x6e, 0x03, 0x45, 0x42, 0xc0,
    0x90, 0x29, 0x2e, 0xce, 0x00, 0x9b, 0x52, 0x14, 0x2f, 0x9b, 0x5c, 0x00, 0x2e, 0x93, 0x41, 0x86, 0x41, 0xe3, 0x04,
    0xae, 0x07, 0x80, 0xab, 0x04, 0x2f, 0x80, 0x91, 0x0a, 0x2f, 0x86, 0x6f, 0x73, 0x0f, 0x07, 0x2f, 0x83, 0x6f, 0xc0,
    0xb2, 0x04, 0x2f, 0x54, 0x42, 0x45, 0x42, 0x12, 0x30, 0x04, 0x2c, 0x11, 0x30, 0x02, 0x2c, 0x11, 0x30, 0x11, 0x30,
    0x02, 0xbc, 0x0f, 0xb8, 0xd2, 0x7f, 0x00, 0xb2, 0x0a, 0x2f, 0x01, 0x2e, 0xfc, 0x00, 0x05, 0x2e, 0xc7, 0x01, 0x10,
    0x1a, 0x02, 0x2f, 0x21, 0x2e, 0xc7, 0x01, 0x03, 0x2d, 0x02, 0x2c, 0x01, 0x30, 0x01, 0x30, 0xb0, 0x6f, 0x98, 0x2e,
    0x95, 0xcf, 0xd1, 0x6f, 0xa0, 0x6f, 0x98, 0x2e, 0x95, 0xcf, 0xe2, 0x6f, 0x9f, 0x52, 0x01, 0x2e, 0xce, 0x00, 0x82,
    0x40, 0x50, 0x42, 0x0c, 0x2c, 0x42, 0x42, 0x11, 0x30, 0x23, 0x2e, 0xd2, 0x00, 0x01, 0x30, 0xb0, 0x6f, 0x98, 0x2e,
    0x95, 0xcf, 0xa0, 0x6f, 0x01, 0x30, 0x98, 0x2e, 0x95, 0xcf, 0x00, 0x2e, 0xfb, 0x6f, 0x00, 0x5f, 0xb8, 0x2e, 0x83,
    0x86, 0x01, 0x30, 0x00, 0x30, 0x94, 0x40, 0x24, 0x18, 0x06, 0x00, 0x53, 0x0e, 0x4f, 0x02, 0xf9, 0x2f, 0xb8, 0x2e,
    0xa9, 0x52, 0x00, 0x2e, 0x60, 0x40, 0x41, 0x40, 0x0d, 0xbc, 0x98, 0xbc, 0xc0, 0x2e, 0x01, 0x0a, 0x0f, 0xb8, 0xab,
    0x52, 0x53, 0x3c, 0x52, 0x40, 0x40, 0x40, 0x4b, 0x00, 0x82, 0x16, 0x26, 0xb9, 0x01, 0xb8, 0x41, 0x40, 0x10, 0x08,
    0x97, 0xb8, 0x01, 0x08, 0xc0, 0x2e, 0x11, 0x30, 0x01, 0x08, 0x43, 0x86, 0x25, 0x40, 0x04, 0x40, 0xd8, 0xbe, 0x2c,
    0x0b, 0x22, 0x11, 0x54, 0x42, 0x03, 0x80, 0x4b, 0x0e, 0xf6, 0x2f, 0xb8, 0x2e, 0x9f, 0x50, 0x10, 0x50, 0xad, 0x52,
    0x05, 0x2e, 0xd3, 0x00, 0xfb, 0x7f, 0x00, 0x2e, 0x13, 0x40, 0x93, 0x42, 0x41, 0x0e, 0xfb, 0x2f, 0x98, 0x2e, 0xa5,
    0xb7, 0x98, 0x2e, 0x87, 0xcf, 0x01, 0x2e, 0xd9, 0x00, 0x00, 0xb2, 0xfb, 0x6f, 0x0b, 0x2f, 0x01, 0x2e, 0x69, 0xf7,
    0xb1, 0x3f, 0x01, 0x08, 0x01, 0x30, 0xf0, 0x5f, 0x23, 0x2e, 0xd9, 0x00, 0x21, 0x2e, 0x69, 0xf7, 0x80, 0x2e, 0x7a,
    0xb7, 0xf0, 0x5f, 0xb8, 0x2e, 0x01, 0x2e, 0xc0, 0xf8, 0x03, 0x2e, 0xfc, 0xf5, 0x15, 0x54, 0xaf, 0x56, 0x82, 0x08,
    0x0b, 0x2e, 0x69, 0xf7, 0xcb, 0x0a, 0xb1, 0x58, 0x80, 0x90, 0xdd, 0xbe, 0x4c, 0x08, 0x5f, 0xb9, 0x59, 0x22, 0x80,
    0x90, 0x07, 0x2f, 0x03, 0x34, 0xc3, 0x08, 0xf2, 0x3a, 0x0a, 0x08, 0x02, 0x35, 0xc0, 0x90, 0x4a, 0x0a, 0x48, 0x22,
    0xc0, 0x2e, 0x23, 0x2e, 0xfc, 0xf5, 0x10, 0x50, 0xfb, 0x7f, 0x98, 0x2e, 0x56, 0xc7, 0x98, 0x2e, 0x49, 0xc3, 0x10,
    0x30, 0xfb, 0x6f, 0xf0, 0x5f, 0x21, 0x2e, 0xcc, 0x00, 0x21, 0x2e, 0xca, 0x00, 0xb8, 0x2e, 0x03, 0x2e, 0xd3, 0x00,
    0x16, 0xb8, 0x02, 0x34, 0x4a, 0x0c, 0x21, 0x2e, 0x2d, 0xf5, 0xc0, 0x2e, 0x23, 0x2e, 0xd3, 0x00, 0x03, 0xbc, 0x21,
    0x2e, 0xd5, 0x00, 0x03, 0x2e, 0xd5, 0x00, 0x40, 0xb2, 0x10, 0x30, 0x21, 0x2e, 0x77, 0x00, 0x01, 0x30, 0x05, 0x2f,
    0x05, 0x2e, 0xd8, 0x00, 0x80, 0x90, 0x01, 0x2f, 0x23, 0x2e, 0x6f, 0xf5, 0xc0, 0x2e, 0x21, 0x2e, 0xd9, 0x00, 0x11,
    0x30, 0x81, 0x08, 0x01, 0x2e, 0x6a, 0xf7, 0x71, 0x3f, 0x23, 0xbd, 0x01, 0x08, 0x02, 0x0a, 0xc0, 0x2e, 0x21, 0x2e,
    0x6a, 0xf7, 0x30, 0x25, 0x00, 0x30, 0x21, 0x2e, 0x5a, 0xf5, 0x10, 0x50, 0x21, 0x2e, 0x7b, 0x00, 0x21, 0x2e, 0x7c,
    0x00, 0xfb, 0x7f, 0x98, 0x2e, 0xc3, 0xb7, 0x40, 0x30, 0x21, 0x2e, 0xd4, 0x00, 0xfb, 0x6f, 0xf0, 0x5f, 0x03, 0x25,
    0x80, 0x2e, 0xaf, 0xb7, 0x80, 0x2e, 0x00, 0xc1, 0x80, 0x2e, 0x00, 0xc1, 0x80, 0x2e, 0x00, 0xc1, 0x80, 0x2e, 0x00,
    0xc1, 0x80, 0x2e, 0x00, 0xc1, 0x80, 0x2e, 0x00, 0xc1, 0x80, 0x2e, 0x00, 0xc1, 0x80, 0x2e, 0x00, 0xc1, 0x80, 0x2e,
    0x00, 0xc1, 0x80, 0x2e, 0x00, 0xc1, 0x80, 0x2e, 0x00, 0xc1, 0x80, 0x2e, 0x00, 0xc1, 0x80, 0x2e, 0x00, 0xc1, 0x80,
    0x2e, 0x00, 0xc1, 0x80, 0x2e, 0x00, 0xc1, 0x01, 0x2e, 0x5d, 0xf7, 0x08, 0xbc, 0x80, 0xac, 0x0e, 0xbb, 0x02, 0x2f,
    0x00, 0x30, 0x41, 0x04, 0x82, 0x06, 0xc0, 0xa4, 0x00, 0x30, 0x11, 0x2f, 0x40, 0xa9, 0x03, 0x2f, 0x40, 0x91, 0x0d,
    0x2f, 0x00, 0xa7, 0x0b, 0x2f, 0x80, 0xb3, 0xb3, 0x58, 0x02, 0x2f, 0x90, 0xa1, 0x26, 0x13, 0x20, 0x23, 0x80, 0x90,
    0x10, 0x30, 0x01, 0x2f, 0xcc, 0x0e, 0x00, 0x2f, 0x00, 0x30, 0xb8, 0x2e, 0xb5, 0x50, 0x18, 0x08, 0x08, 0xbc, 0x88,
    0xb6, 0x0d, 0x17, 0xc6, 0xbd, 0x56, 0xbc, 0xb7, 0x58, 0xda, 0xba, 0x04, 0x01, 0x1d, 0x0a, 0x10, 0x50, 0x05, 0x30,
    0x32, 0x25, 0x45, 0x03, 0xfb, 0x7f, 0xf6, 0x30, 0x21, 0x25, 0x98, 0x2e, 0x37, 0xca, 0x16, 0xb5, 0x9a, 0xbc, 0x06,
    0xb8, 0x80, 0xa8, 0x41, 0x0a, 0x0e, 0x2f, 0x80, 0x90, 0x02, 0x2f, 0x2d, 0x50, 0x48, 0x0f, 0x09, 0x2f, 0xbf, 0xa0,
    0x04, 0x2f, 0xbf, 0x90, 0x06, 0x2f, 0xb7, 0x54, 0xca, 0x0f, 0x03, 0x2f, 0x00, 0x2e, 0x02, 0x2c, 0xb7, 0x52, 0x2d,
    0x52, 0xf2, 0x33, 0x98, 0x2e, 0xd9, 0xc0, 0xfb, 0x6f, 0xf1, 0x37, 0xc0, 0x2e, 0x01, 0x08, 0xf0, 0x5f, 0xbf, 0x56,
    0xb9, 0x54, 0xd0, 0x40, 0xc4, 0x40, 0x0b, 0x2e, 0xfd, 0xf3, 0xbf, 0x52, 0x90, 0x42, 0x94, 0x42, 0x95, 0x42, 0x05,
    0x30, 0xc1, 0x50, 0x0f, 0x88, 0x06, 0x40, 0x04, 0x41, 0x96, 0x42, 0xc5, 0x42, 0x48, 0xbe, 0x73, 0x30, 0x0d, 0x2e,
    0xd8, 0x00, 0x4f, 0xba, 0x84, 0x42, 0x03, 0x42, 0x81, 0xb3, 0x02, 0x2f, 0x2b, 0x2e, 0x6f, 0xf5, 0x06, 0x2d, 0x05,
    0x2e, 0x77, 0xf7, 0xbd, 0x56, 0x93, 0x08, 0x25, 0x2e, 0x77, 0xf7, 0xbb, 0x54, 0x25, 0x2e, 0xc2, 0xf5, 0x07, 0x2e,
    0xfd, 0xf3, 0x42, 0x30, 0xb4, 0x33, 0xda, 0x0a, 0x4c, 0x00, 0x27, 0x2e, 0xfd, 0xf3, 0x43, 0x40, 0xd4, 0x3f, 0xdc,
    0x08, 0x43, 0x42, 0x00, 0x2e, 0x00, 0x2e, 0x43, 0x40, 0x24, 0x30, 0xdc, 0x0a, 0x43, 0x42, 0x04, 0x80, 0x03, 0x2e,
    0xfd, 0xf3, 0x4a, 0x0a, 0x23, 0x2e, 0xfd, 0xf3, 0x61, 0x34, 0xc0, 0x2e, 0x01, 0x42, 0x00, 0x2e, 0x60, 0x50, 0x1a,
    0x25, 0x7a, 0x86, 0xe0, 0x7f, 0xf3, 0x7f, 0x03, 0x25, 0xc3, 0x52, 0x41, 0x84, 0xdb, 0x7f, 0x33, 0x30, 0x98, 0x2e,
    0x16, 0xc2, 0x1a, 0x25, 0x7d, 0x82, 0xf0, 0x6f, 0xe2, 0x6f, 0x32, 0x25, 0x16, 0x40, 0x94, 0x40, 0x26, 0x01, 0x85,
    0x40, 0x8e, 0x17, 0xc4, 0x42, 0x6e, 0x03, 0x95, 0x42, 0x41, 0x0e, 0xf4, 0x2f, 0xdb, 0x6f, 0xa0, 0x5f, 0xb8, 0x2e,
    0xb0, 0x51, 0xfb, 0x7f, 0x98, 0x2e, 0xe8, 0x0d, 0x5a, 0x25, 0x98, 0x2e, 0x0f, 0x0e, 0xcb, 0x58, 0x32, 0x87, 0xc4,
    0x7f, 0x65, 0x89, 0x6b, 0x8d, 0xc5, 0x5a, 0x65, 0x7f, 0xe1, 0x7f, 0x83, 0x7f, 0xa6, 0x7f, 0x74, 0x7f, 0xd0, 0x7f,
    0xb6, 0x7f, 0x94, 0x7f, 0x17, 0x30, 0xc7, 0x52, 0xc9, 0x54, 0x51, 0x7f, 0x00, 0x2e, 0x85, 0x6f, 0x42, 0x7f, 0x00,
    0x2e, 0x51, 0x41, 0x45, 0x81, 0x42, 0x41, 0x13, 0x40, 0x3b, 0x8a, 0x00, 0x40, 0x4b, 0x04, 0xd0, 0x06, 0xc0, 0xac,
    0x85, 0x7f, 0x02, 0x2f, 0x02, 0x30, 0x51, 0x04, 0xd3, 0x06, 0x41, 0x84, 0x05, 0x30, 0x5d, 0x02, 0xc9, 0x16, 0xdf,
    0x08, 0xd3, 0x00, 0x8d, 0x02, 0xaf, 0xbc, 0xb1, 0xb9, 0x59, 0x0a, 0x65, 0x6f, 0x11, 0x43, 0xa1, 0xb4, 0x52, 0x41,
    0x53, 0x41, 0x01, 0x43, 0x34, 0x7f, 0x65, 0x7f, 0x26, 0x31, 0xe5, 0x6f, 0xd4, 0x6f, 0x98, 0x2e, 0x37, 0xca, 0x32,
    0x6f, 0x75, 0x6f, 0x83, 0x40, 0x42, 0x41, 0x23, 0x7f, 0x12, 0x7f, 0xf6, 0x30, 0x40, 0x25, 0x51, 0x25, 0x98, 0x2e,
    0x37, 0xca, 0x14, 0x6f, 0x20, 0x05, 0x70, 0x6f, 0x25, 0x6f, 0x69, 0x07, 0xa2, 0x6f, 0x31, 0x6f, 0x0b, 0x30, 0x04,
    0x42, 0x9b, 0x42, 0x8b, 0x42, 0x55, 0x42, 0x32, 0x7f, 0x40, 0xa9, 0xc3, 0x6f, 0x71, 0x7f, 0x02, 0x30, 0xd0, 0x40,
    0xc3, 0x7f, 0x03, 0x2f, 0x40, 0x91, 0x15, 0x2f, 0x00, 0xa7, 0x13, 0x2f, 0x00, 0xa4, 0x11, 0x2f, 0x84, 0xbd, 0x98,
    0x2e, 0x79, 0xca, 0x55, 0x6f, 0xb7, 0x54, 0x54, 0x41, 0x82, 0x00, 0xf3, 0x3f, 0x45, 0x41, 0xcb, 0x02, 0xf6, 0x30,
    0x98, 0x2e, 0x37, 0xca, 0x35, 0x6f, 0xa4, 0x6f, 0x41, 0x43, 0x03, 0x2c, 0x00, 0x43, 0xa4, 0x6f, 0x35, 0x6f, 0x17,
    0x30, 0x42, 0x6f, 0x51, 0x6f, 0x93, 0x40, 0x42, 0x82, 0x00, 0x41, 0xc3, 0x00, 0x03, 0x43, 0x51, 0x7f, 0x00, 0x2e,
    0x94, 0x40, 0x41, 0x41, 0x4c, 0x02, 0xc4, 0x6f, 0xd1, 0x56, 0x63, 0x0e, 0x74, 0x6f, 0x51, 0x43, 0xa5, 0x7f, 0x8a,
    0x2f, 0x09, 0x2e, 0xd8, 0x00, 0x01, 0xb3, 0x21, 0x2f, 0xcb, 0x58, 0x90, 0x6f, 0x13, 0x41, 0xb6, 0x6f, 0xe4, 0x7f,
    0x00, 0x2e, 0x91, 0x41, 0x14, 0x40, 0x92, 0x41, 0x15, 0x40, 0x17, 0x2e, 0x6f, 0xf5, 0xb6, 0x7f, 0xd0, 0x7f, 0xcb,
    0x7f, 0x98, 0x2e, 0x00, 0x0c, 0x07, 0x15, 0xc2, 0x6f, 0x14, 0x0b, 0x29, 0x2e, 0x6f, 0xf5, 0xc3, 0xa3, 0xc1, 0x8f,
    0xe4, 0x6f, 0xd0, 0x6f, 0xe6, 0x2f, 0x14, 0x30, 0x05, 0x2e, 0x6f, 0xf5, 0x14, 0x0b, 0x29, 0x2e, 0x6f, 0xf5, 0x18,
    0x2d, 0xcd, 0x56, 0x04, 0x32, 0xb5, 0x6f, 0x1c, 0x01, 0x51, 0x41, 0x52, 0x41, 0xc3, 0x40, 0xb5, 0x7f, 0xe4, 0x7f,
    0x98, 0x2e, 0x1f, 0x0c, 0xe4, 0x6f, 0x21, 0x87, 0x00, 0x43, 0x04, 0x32, 0xcf, 0x54, 0x5a, 0x0e, 0xef, 0x2f, 0x15,
    0x54, 0x09, 0x2e, 0x77, 0xf7, 0x22, 0x0b, 0x29, 0x2e, 0x77, 0xf7, 0xfb, 0x6f, 0x50, 0x5e, 0xb8, 0x2e, 0x10, 0x50,
    0x01, 0x2e, 0xd4, 0x00, 0x00, 0xb2, 0xfb, 0x7f, 0x51, 0x2f, 0x01, 0xb2, 0x48, 0x2f, 0x02, 0xb2, 0x42, 0x2f, 0x03,
    0x90, 0x56, 0x2f, 0xd7, 0x52, 0x79, 0x80, 0x42, 0x40, 0x81, 0x84, 0x00, 0x40, 0x42, 0x42, 0x98, 0x2e, 0x93, 0x0c,
    0xd9, 0x54, 0xd7, 0x50, 0xa1, 0x40, 0x98, 0xbd, 0x82, 0x40, 0x3e, 0x82, 0xda, 0x0a, 0x44, 0x40, 0x8b, 0x16, 0xe3,
    0x00, 0x53, 0x42, 0x00, 0x2e, 0x43, 0x40, 0x9a, 0x02, 0x52, 0x42, 0x00, 0x2e, 0x41, 0x40, 0x15, 0x54, 0x4a, 0x0e,
    0x3a, 0x2f, 0x3a, 0x82, 0x00, 0x30, 0x41, 0x40, 0x21, 0x2e, 0x85, 0x0f, 0x40, 0xb2, 0x0a, 0x2f, 0x98, 0x2e, 0xb1,
    0x0c, 0x98, 0x2e, 0x45, 0x0e, 0x98, 0x2e, 0x5b, 0x0e, 0xfb, 0x6f, 0xf0, 0x5f, 0x00, 0x30, 0x80, 0x2e, 0xce, 0xb7,
    0xdd, 0x52, 0xd3, 0x54, 0x42, 0x42, 0x4f, 0x84, 0x73, 0x30, 0xdb, 0x52, 0x83, 0x42, 0x1b, 0x30, 0x6b, 0x42, 0x23,
    0x30, 0x27, 0x2e, 0xd7, 0x00, 0x37, 0x2e, 0xd4, 0x00, 0x21, 0x2e, 0xd6, 0x00, 0x7a, 0x84, 0x17, 0x2c, 0x42, 0x42,
    0x30, 0x30, 0x21, 0x2e, 0xd4, 0x00, 0x12, 0x2d, 0x21, 0x30, 0x00, 0x30, 0x23, 0x2e, 0xd4, 0x00, 0x21, 0x2e, 0x7b,
    0xf7, 0x0b, 0x2d, 0x17, 0x30, 0x98, 0x2e, 0x51, 0x0c, 0xd5, 0x50, 0x0c, 0x82, 0x72, 0x30, 0x2f, 0x2e, 0xd4, 0x00,
    0x25, 0x2e, 0x7b, 0xf7, 0x40, 0x42, 0x00, 0x2e, 0xfb, 0x6f, 0xf0, 0x5f, 0xb8, 0x2e, 0x70, 0x50, 0x0a, 0x25, 0x39,
    0x86, 0xfb, 0x7f, 0xe1, 0x32, 0x62, 0x30, 0x98, 0x2e, 0xc2, 0xc4, 0xb5, 0x56, 0xa5, 0x6f, 0xab, 0x08, 0x91, 0x6f,
    0x4b, 0x08, 0xdf, 0x56, 0xc4, 0x6f, 0x23, 0x09, 0x4d, 0xba, 0x93, 0xbc, 0x8c, 0x0b, 0xd1, 0x6f, 0x0b, 0x09, 0xcb,
    0x52, 0xe1, 0x5e, 0x56, 0x42, 0xaf, 0x09, 0x4d, 0xba, 0x23, 0xbd, 0x94, 0x0a, 0xe5, 0x6f, 0x68, 0xbb, 0xeb, 0x08,
    0xbd, 0xb9, 0x63, 0xbe, 0xfb, 0x6f, 0x52, 0x42, 0xe3, 0x0a, 0xc0, 0x2e, 0x43, 0x42, 0x90, 0x5f, 0xd1, 0x50, 0x03,
    0x2e, 0x25, 0xf3, 0x13, 0x40, 0x00, 0x40, 0x9b, 0xbc, 0x9b, 0xb4, 0x08, 0xbd, 0xb8, 0xb9, 0x98, 0xbc, 0xda, 0x0a,
    0x08, 0xb6, 0x89, 0x16, 0xc0, 0x2e, 0x19, 0x00, 0x62, 0x02, 0x10, 0x50, 0xfb, 0x7f, 0x98, 0x2e, 0x81, 0x0d, 0x01,
    0x2e, 0xd4, 0x00, 0x31, 0x30, 0x08, 0x04, 0xfb, 0x6f, 0x01, 0x30, 0xf0, 0x5f, 0x23, 0x2e, 0xd6, 0x00, 0x21, 0x2e,
    0xd7, 0x00, 0xb8, 0x2e, 0x01, 0x2e, 0xd7, 0x00, 0x03, 0x2e, 0xd6, 0x00, 0x48, 0x0e, 0x01, 0x2f, 0x80, 0x2e, 0x1f,
    0x0e, 0xb8, 0x2e, 0xe3, 0x50, 0x21, 0x34, 0x01, 0x42, 0x82, 0x30, 0xc1, 0x32, 0x25, 0x2e, 0x62, 0xf5, 0x01, 0x00,
    0x22, 0x30, 0x01, 0x40, 0x4a, 0x0a, 0x01, 0x42, 0xb8, 0x2e, 0xe3, 0x54, 0xf0, 0x3b, 0x83, 0x40, 0xd8, 0x08, 0xe5,
    0x52, 0x83, 0x42, 0x00, 0x30, 0x83, 0x30, 0x50, 0x42, 0xc4, 0x32, 0x27, 0x2e, 0x64, 0xf5, 0x94, 0x00, 0x50, 0x42,
    0x40, 0x42, 0xd3, 0x3f, 0x84, 0x40, 0x7d, 0x82, 0xe3, 0x08, 0x40, 0x42, 0x83, 0x42, 0xb8, 0x2e, 0xdd, 0x52, 0x00,
    0x30, 0x40, 0x42, 0x7c, 0x86, 0xb9, 0x52, 0x09, 0x2e, 0x70, 0x0f, 0xbf, 0x54, 0xc4, 0x42, 0xd3, 0x86, 0x54, 0x40,
    0x55, 0x40, 0x94, 0x42, 0x85, 0x42, 0x21, 0x2e, 0xd7, 0x00, 0x42, 0x40, 0x25, 0x2e, 0xfd, 0xf3, 0xc0, 0x42, 0x7e,
    0x82, 0x05, 0x2e, 0x7d, 0x00, 0x80, 0xb2, 0x14, 0x2f, 0x05, 0x2e, 0x89, 0x00, 0x27, 0xbd, 0x2f, 0xb9, 0x80, 0x90,
    0x02, 0x2f, 0x21, 0x2e, 0x6f, 0xf5, 0x0c, 0x2d, 0x07, 0x2e, 0x71, 0x0f, 0x14, 0x30, 0x1c, 0x09, 0x05, 0x2e, 0x77,
    0xf7, 0xbd, 0x56, 0x47, 0xbe, 0x93, 0x08, 0x94, 0x0a, 0x25, 0x2e, 0x77, 0xf7, 0xe7, 0x54, 0x50, 0x42, 0x4a, 0x0e,
    0xfc, 0x2f, 0xb8, 0x2e, 0x50, 0x50, 0x02, 0x30, 0x43, 0x86, 0xe5, 0x50, 0xfb, 0x7f, 0xe3, 0x7f, 0xd2, 0x7f, 0xc0,
    0x7f, 0xb1, 0x7f, 0x00, 0x2e, 0x41, 0x40, 0x00, 0x40, 0x48, 0x04, 0x98, 0x2e, 0x74, 0xc0, 0x1e, 0xaa, 0xd3, 0x6f,
    0x14, 0x30, 0xb1, 0x6f, 0xe3, 0x22, 0xc0, 0x6f, 0x52, 0x40, 0xe4, 0x6f, 0x4c, 0x0e, 0x12, 0x42, 0xd3, 0x7f, 0xeb,
    0x2f, 0x03, 0x2e, 0x86, 0x0f, 0x40, 0x90, 0x11, 0x30, 0x03, 0x2f, 0x23, 0x2e, 0x86, 0x0f, 0x02, 0x2c, 0x00, 0x30,
    0xd0, 0x6f, 0xfb, 0x6f, 0xb0, 0x5f, 0xb8, 0x2e, 0x40, 0x50, 0xf1, 0x7f, 0x0a, 0x25, 0x3c, 0x86, 0xeb, 0x7f, 0x41,
    0x33, 0x22, 0x30, 0x98, 0x2e, 0xc2, 0xc4, 0xd3, 0x6f, 0xf4, 0x30, 0xdc, 0x09, 0x47, 0x58, 0xc2, 0x6f, 0x94, 0x09,
    0xeb, 0x58, 0x6a, 0xbb, 0xdc, 0x08, 0xb4, 0xb9, 0xb1, 0xbd, 0xe9, 0x5a, 0x95, 0x08, 0x21, 0xbd, 0xf6, 0xbf, 0x77,
    0x0b, 0x51, 0xbe, 0xf1, 0x6f, 0xeb, 0x6f, 0x52, 0x42, 0x54, 0x42, 0xc0, 0x2e, 0x43, 0x42, 0xc0, 0x5f, 0x50, 0x50,
    0xf5, 0x50, 0x31, 0x30, 0x11, 0x42, 0xfb, 0x7f, 0x7b, 0x30, 0x0b, 0x42, 0x11, 0x30, 0x02, 0x80, 0x23, 0x33, 0x01,
    0x42, 0x03, 0x00, 0x07, 0x2e, 0x80, 0x03, 0x05, 0x2e, 0xd3, 0x00, 0x23, 0x52, 0xe2, 0x7f, 0xd3, 0x7f, 0xc0, 0x7f,
    0x98, 0x2e, 0xb6, 0x0e, 0xd1, 0x6f, 0x08, 0x0a, 0x1a, 0x25, 0x7b, 0x86, 0xd0, 0x7f, 0x01, 0x33, 0x12, 0x30, 0x98,
    0x2e, 0xc2, 0xc4, 0xd1, 0x6f, 0x08, 0x0a, 0x00, 0xb2, 0x0d, 0x2f, 0xe3, 0x6f, 0x01, 0x2e, 0x80, 0x03, 0x51, 0x30,
    0xc7, 0x86, 0x23, 0x2e, 0x21, 0xf2, 0x08, 0xbc, 0xc0, 0x42, 0x98, 0x2e, 0xa5, 0xb7, 0x00, 0x2e, 0x00, 0x2e, 0xd0,
    0x2e, 0xb0, 0x6f, 0x0b, 0xb8, 0x03, 0x2e, 0x1b, 0x00, 0x08, 0x1a, 0xb0, 0x7f, 0x70, 0x30, 0x04, 0x2f, 0x21, 0x2e,
    0x21, 0xf2, 0x00, 0x2e, 0x00, 0x2e, 0xd0, 0x2e, 0x98, 0x2e, 0x6d, 0xc0, 0x98, 0x2e, 0x5d, 0xc0, 0xed, 0x50, 0x98,
    0x2e, 0x44, 0xcb, 0xef, 0x50, 0x98, 0x2e, 0x46, 0xc3, 0xf1, 0x50, 0x98, 0x2e, 0x53, 0xc7, 0x35, 0x50, 0x98, 0x2e,
    0x64, 0xcf, 0x10, 0x30, 0x98, 0x2e, 0xdc, 0x03, 0x20, 0x26, 0xc0, 0x6f, 0x02, 0x31, 0x12, 0x42, 0xab, 0x33, 0x0b,
    0x42, 0x37, 0x80, 0x01, 0x30, 0x01, 0x42, 0xf3, 0x37, 0xf7, 0x52, 0xfb, 0x50, 0x44, 0x40, 0xa2, 0x0a, 0x42, 0x42,
    0x8b, 0x31, 0x09, 0x2e, 0x5e, 0xf7, 0xf9, 0x54, 0xe3, 0x08, 0x83, 0x42, 0x1b, 0x42, 0x23, 0x33, 0x4b, 0x00, 0xbc,
    0x84, 0x0b, 0x40, 0x33, 0x30, 0x83, 0x42, 0x0b, 0x42, 0xe0, 0x7f, 0xd1, 0x7f, 0x98, 0x2e, 0x58, 0xb7, 0xd1, 0x6f,
    0x80, 0x30, 0x40, 0x42, 0x03, 0x30, 0xe0, 0x6f, 0xf3, 0x54, 0x04, 0x30, 0x00, 0x2e, 0x00, 0x2e, 0x01, 0x89, 0x62,
    0x0e, 0xfa, 0x2f, 0x43, 0x42, 0x11, 0x30, 0xfb, 0x6f, 0xc0, 0x2e, 0x01, 0x42, 0xb0, 0x5f, 0xc1, 0x4a, 0x00, 0x00,
    0x6d, 0x57, 0x00, 0x00, 0x77, 0x8e, 0x00, 0x00, 0xe0, 0xff, 0xff, 0xff, 0xd3, 0xff, 0xff, 0xff, 0xe5, 0xff, 0xff,
    0xff, 0xee, 0xe1, 0xff, 0xff, 0x7c, 0x13, 0x00, 0x00, 0x46, 0xe6, 0xff, 0xff, 0x00, 0x00, 0x00, 0x00, 0x00, 0x00,
    0x00, 0x00, 0x00, 0x00, 0x00, 0x00, 0x00, 0x00, 0x00, 0x00, 0x00, 0x00, 0x00, 0x00, 0x00, 0x00, 0x00, 0x00, 0x00,
    0x00, 0x00, 0x00, 0x00, 0x00, 0x00, 0x00, 0x00, 0x00, 0x00, 0x00, 0x00, 0x00, 0x00, 0x00, 0x00, 0x00, 0x00, 0x00,
    0x00, 0x00, 0x00, 0x00, 0x00, 0x00, 0x00, 0x00, 0x00, 0x00, 0x00, 0x00, 0x00, 0x00, 0x80, 0x2e, 0x00, 0xc1, 0x80,
    0x2e, 0x00, 0xc1, 0x80, 0x2e, 0x00, 0xc1, 0x80, 0x2e, 0x00, 0xc1, 0x80, 0x2e, 0x00, 0xc1, 0x80, 0x2e, 0x00, 0xc1,
    0x80, 0x2e, 0x00, 0xc1, 0x80, 0x2e, 0x00, 0xc1, 0x80, 0x2e, 0x00, 0xc1, 0x80, 0x2e, 0x00, 0xc1, 0x80, 0x2e, 0x00,
    0xc1, 0x80, 0x2e, 0x00, 0xc1, 0x80, 0x2e, 0x00, 0xc1, 0x80, 0x2e, 0x00, 0xc1, 0x80, 0x2e, 0x00, 0xc1, 0x80, 0x2e,
    0x00, 0xc1, 0x80, 0x2e, 0x00, 0xc1, 0x80, 0x2e, 0x00, 0xc1, 0x80, 0x2e, 0x00, 0xc1, 0x80, 0x2e, 0x00, 0xc1, 0x80,
    0x2e, 0x00, 0xc1, 0x80, 0x2e, 0x00, 0xc1, 0x80, 0x2e, 0x00, 0xc1, 0x80, 0x2e, 0x00, 0xc1, 0x80, 0x2e, 0x00, 0xc1,
    0x80, 0x2e, 0x00, 0xc1, 0x80, 0x2e, 0x00, 0xc1, 0x80, 0x2e, 0x00, 0xc1, 0x80, 0x2e, 0x00, 0xc1, 0x80, 0x2e, 0x00,
    0xc1, 0x80, 0x2e, 0x00, 0xc1, 0x80, 0x2e, 0x00, 0xc1, 0x80, 0x2e, 0x00, 0xc1, 0x80, 0x2e, 0x00, 0xc1, 0x80, 0x2e,
    0x00, 0xc1, 0x80, 0x2e, 0x00, 0xc1, 0x80, 0x2e, 0x00, 0xc1, 0x80, 0x2e, 0x00, 0xc1, 0x80, 0x2e, 0x00, 0xc1, 0x80,
    0x2e, 0x00, 0xc1, 0x80, 0x2e, 0x00, 0xc1, 0x80, 0x2e, 0x00, 0xc1, 0x80, 0x2e, 0x00, 0xc1, 0x80, 0x2e, 0x00, 0xc1,
    0x80, 0x2e, 0x00, 0xc1, 0x80, 0x2e, 0x00, 0xc1, 0x80, 0x2e, 0x00, 0xc1, 0x80, 0x2e, 0x00, 0xc1, 0x80, 0x2e, 0x00,
    0xc1, 0x80, 0x2e, 0x00, 0xc1, 0x80, 0x2e, 0x00, 0xc1, 0x80, 0x2e, 0x00, 0xc1, 0x80, 0x2e, 0x00, 0xc1, 0x80, 0x2e,
    0x00, 0xc1, 0x80, 0x2e, 0x00, 0xc1, 0x80, 0x2e, 0x00, 0xc1, 0x80, 0x2e, 0x00, 0xc1, 0x80, 0x2e, 0x00, 0xc1, 0x80,
    0x2e, 0x00, 0xc1
};

/* USER CODE END PV */

void SystemClock_Config(void);
/* USER CODE BEGIN PFP */
void BMI270_I2C_init();
void BMI270_I2C_process();
int I2C1_byteRead(char saddr, char maddr, uint8_t* data);
int I2C1_byteWrite(char saddr, char maddr, uint8_t* data);
int I2C1_burstRead(char saddr, char maddr, int n, uint8_t* data);
int I2C1_burstWrite(char saddr, char maddr, int n, uint8_t* data);

void BMI270_SPI_init();
void BMI270_SPI_process();
void SPI1_transmit(uint8_t *data, uint32_t size);
void SPI1_receive(uint8_t *data, uint32_t size);
/* USER CODE END PFP */

/* USER CODE BEGIN 0 */
#ifdef __GNUC__
#define PUTCHAR_PROTOTYPE int __io_putchar(int ch)
#else
#define PUTCHAR_PROTOTYPE int fputc(int ch, FILE *f)
#endif

PUTCHAR_PROTOTYPE
{
	HAL_UART_Transmit(&huart2, (uint8_t*)&ch, 1, HAL_MAX_DELAY);
	return ch;
}
/* USER CODE END 0 */

int main(void)
{

  /* USER CODE BEGIN 1 */
	// определяем где выполняется программа, и корректируем расположение
	// таблицы векторов
	uint32_t retPCasm(void); // небольшая функция для определения где
	// выполняется программа в FLASH или RAM
	if ((retPCasm() & 0x20000000) != 0)
	{
		*((uint32_t *)0xe000ed08) = 0x20000000; /* FlagDebugInRAM=1;*/
	}
  /* USER CODE END 1 */

  /* MCU Configuration--------------------------------------------------------*/

  /* Reset of all peripherals, Initializes the Flash interface and the Systick. */
  HAL_Init();

  /* Configure the system clock */
  SystemClock_Config();

  /* Initialize all configured peripherals */
  MX_GPIO_Init();
  MX_DMA_Init();
  MX_SPI1_Init();
  MX_TIM5_Init();
  MX_RTC_Init();
  MX_I2C1_Init();
  MX_USART2_UART_Init();

  /* Infinite loop */
  /* USER CODE BEGIN WHILE */

	HAL_Delay(1000);
//	BMI270_I2C_init();
	BMI270_SPI_init();

  void main_BMI270(void);
  main_BMI270();
  while (1)
  {
//	  BMI270_I2C_process();
	  BMI270_SPI_process();
    /* USER CODE END WHILE */

  }
}

void SystemClock_Config(void)
{
  RCC_OscInitTypeDef RCC_OscInitStruct = {0};
  RCC_ClkInitTypeDef RCC_ClkInitStruct = {0};

  /** Configure the main internal regulator output voltage
  */
  __HAL_RCC_PWR_CLK_ENABLE();
  __HAL_PWR_VOLTAGESCALING_CONFIG(PWR_REGULATOR_VOLTAGE_SCALE1);

  /** Initializes the RCC Oscillators according to the specified parameters
  * in the RCC_OscInitTypeDef structure.
  */
  RCC_OscInitStruct.OscillatorType = RCC_OSCILLATORTYPE_HSI|RCC_OSCILLATORTYPE_LSE;
  RCC_OscInitStruct.LSEState = RCC_LSE_ON;
  RCC_OscInitStruct.HSIState = RCC_HSI_ON;
  RCC_OscInitStruct.HSICalibrationValue = RCC_HSICALIBRATION_DEFAULT;
  RCC_OscInitStruct.PLL.PLLState = RCC_PLL_ON;
  RCC_OscInitStruct.PLL.PLLSource = RCC_PLLSOURCE_HSI;
  RCC_OscInitStruct.PLL.PLLM = 8;
  RCC_OscInitStruct.PLL.PLLN = 100;
  RCC_OscInitStruct.PLL.PLLP = RCC_PLLP_DIV2;
  RCC_OscInitStruct.PLL.PLLQ = 4;
  if (HAL_RCC_OscConfig(&RCC_OscInitStruct) != HAL_OK)
  {
    Error_Handler();
  }

  /** Initializes the CPU, AHB and APB buses clocks
  */
  RCC_ClkInitStruct.ClockType = RCC_CLOCKTYPE_HCLK|RCC_CLOCKTYPE_SYSCLK
                              |RCC_CLOCKTYPE_PCLK1|RCC_CLOCKTYPE_PCLK2;
  RCC_ClkInitStruct.SYSCLKSource = RCC_SYSCLKSOURCE_PLLCLK;
  RCC_ClkInitStruct.AHBCLKDivider = RCC_SYSCLK_DIV1;
  RCC_ClkInitStruct.APB1CLKDivider = RCC_HCLK_DIV2;
  RCC_ClkInitStruct.APB2CLKDivider = RCC_HCLK_DIV1;

  if (HAL_RCC_ClockConfig(&RCC_ClkInitStruct, FLASH_LATENCY_3) != HAL_OK)
  {
    Error_Handler();
  }
}

/* USER CODE BEGIN 4 */

void BMI270_I2C_init()
{
	HAL_GPIO_WritePin(SDO_GPIO_Port, SDO_Pin, GPIO_PIN_RESET);
	/*-[ I2C Bus Scanning ]-*/
	uint8_t i = 0, ret;
	printf("%s", StartMSG);
	printf("%s", Space);
    for (i = 1; i < 128; ++i)
    {
        if (i % 16 == 0)
        {
        	printf("%s", NewLine);
        }
        ret = HAL_I2C_IsDeviceReady(&hi2c1, (uint16_t)(i<<1), 3, 5);
        if (ret != HAL_OK) /* No ACK Received At That Address */
        {
        	printf("%s", Space);
        }
        else if(ret == HAL_OK)
        {
            printf("0x%X", i);
            if (i == 0x68 || i == 0x69) // MPU-6050, BMI270
            {
          	  i2c_address = i;
            }
            if (i == 0x53 || i == 0x1D) // ADXL345
            {
          	  i2c_address = i;
            }
        }
    }
    printf("%s", EndMSG);
    /*--[ Scanning Done ]--*/
    uint8_t chip_address;
    I2C1_byteRead(i2c_address, 0x00, &chip_address);
//    HAL_I2C_Mem_Read(&hi2c1, i2c_address << 1, 0x00, 1, &chip_address, 1, 100);
    printf("chip id: 0x%X\r\n", chip_address);

    // Soft reset
#define BMI_ADDRESS_RESET 		0x7E
#define BMI_VALUE_SOFT_RESET 	0xB6
    temp[0] = BMI_VALUE_SOFT_RESET;
    I2C1_byteWrite(i2c_address, BMI_ADDRESS_RESET, temp);
    HAL_Delay(10);

    // Write config file
#define BMI_ADDRESS_PWR_CONFIG 	0x7C
#define BMI_ADDRESS_INIT_CTRL 	0x59
#define BMI_ADDRESS_INIT_DATA 	0x5E
    temp[0] = 0x00; // value to disbale pwr save
    I2C1_byteWrite(i2c_address, BMI_ADDRESS_PWR_CONFIG, temp);
    HAL_Delay(1);
    // Prepare for loading
    I2C1_byteWrite(i2c_address, BMI_ADDRESS_INIT_CTRL, temp);
	// Write the whole thing
	I2C1_burstWrite(i2c_address, BMI_ADDRESS_INIT_DATA, 8192, bmi270_Config_File);
	// Finish loading
	temp[0] = 0x01;
	I2C1_byteWrite(i2c_address, BMI_ADDRESS_INIT_CTRL, temp);
	HAL_Delay(20);

	// Verify it worked
#define BMI_ADDRESS_INIT_STATUS 0x21
	I2C1_byteRead(i2c_address, BMI_ADDRESS_INIT_STATUS, temp);
	if (temp[0] != 0x01)
	{
		printf("ERROR CONFIG\r\n");
	}

	// Set normal power mode
#define BMI_ADDRESS_PWR_CTRL 	0x7D
#define BMI_VALUE_PWR_CTRL		0x0E
	temp[0] = BMI_VALUE_PWR_CTRL;
	I2C1_byteWrite(i2c_address, BMI_ADDRESS_PWR_CTRL, temp);

#define BMI_ADDRESS_ACC_CONF 	0x40
#define BMI_ADDRESS_GYR_CONF 	0x42
#define BMI_VALUE_ACC_CONF 		0xA8
#define BMI_VALUE_GYR_CONF 		0xA9
	temp[0] = BMI_VALUE_ACC_CONF;
	I2C1_byteWrite(i2c_address, BMI_ADDRESS_ACC_CONF, temp);
	temp[0] = BMI_VALUE_GYR_CONF;
	I2C1_byteWrite(i2c_address, BMI_ADDRESS_GYR_CONF, temp);

#define BMI_VALUE_PWR_CONF_DISABLE 0x02
	temp[0] = BMI_VALUE_PWR_CONF_DISABLE;
	I2C1_byteWrite(i2c_address, BMI_ADDRESS_PWR_CONFIG, temp);

	printf("BMI270 is configured\r\n");
}

void BMI270_I2C_process()
{
#define BMI_ADDRESS_SENS_BEGN 	0x0C
	uint16_t ax;
	uint16_t ay;
	uint16_t az;
	uint16_t gx;
	uint16_t gy;
	uint16_t gz;

	I2C1_burstRead(i2c_address, BMI_ADDRESS_SENS_BEGN, 12, temp);
	// accelerometer
	ax = (temp[1]<<8) | (temp[0]);
	ay = (temp[3]<<8) | (temp[2]);
	az = (temp[5]<<8) | (temp[4]);
	// gyro
	gx = (temp[7]<<8)  | (temp[6]);
	gy = (temp[9]<<8)  | (temp[8]);
	gz = (temp[11]<<8) | (temp[10]);
	printf("Accel: x = %d, y = %d, z = %d\r\n", ax, ay, az);
	printf("Gyro: x = %d, y = %d, z = %d\r\n", gx, gy, gz);

	HAL_Delay(100);
}

void BMI270_SPI_init()
{
    uint8_t dummy = 0x00;
    uint8_t chip_address;
    uint8_t data[2];
    data[0] = 0x00;
    HAL_GPIO_WritePin(BMI270_CS_GPIO_Port, BMI270_CS_Pin, GPIO_PIN_RESET);
    SPI1_transmit(&dummy, 1);
    SPI1_transmit(data, 1);
    SPI1_receive(&chip_address, 1);
    HAL_GPIO_WritePin(BMI270_CS_GPIO_Port, BMI270_CS_Pin, GPIO_PIN_SET);
    printf("chip id: 0x%X\r\n", chip_address);
}

void BMI270_SPI_process()
{
	printf("process\r\n");
	HAL_Delay(1000);
	return;
#define BMI_ADDRESS_SENS_BEGN 	0x0C
	uint16_t ax;
	uint16_t ay;
	uint16_t az;
	uint16_t gx;
	uint16_t gy;
	uint16_t gz;

//	I2C1_burstRead(i2c_address, BMI_ADDRESS_SENS_BEGN, 12, temp);
	SPI1_receive(temp, 12);
	// accelerometer
	ax = (temp[1]<<8) | (temp[0]);
	ay = (temp[3]<<8) | (temp[2]);
	az = (temp[5]<<8) | (temp[4]);
	// gyro
	gx = (temp[7]<<8)  | (temp[6]);
	gy = (temp[9]<<8)  | (temp[8]);
	gz = (temp[11]<<8) | (temp[10]);
	printf("Accel: x = %d, y = %d, z = %d\r\n", ax, ay, az);
	printf("Gyro: x = %d, y = %d, z = %d\r\n", gx, gy, gz);

	HAL_Delay(100);
}

// it works!
// https://github.com/ENG-EDISON/STM32_I2C1_I2C2_USART2_MPU6050_BareMetal
int I2C1_byteRead(char saddr, char maddr, uint8_t* data)
{
	volatile uint32_t tmp = 0;
	while (I2C1->SR2 & I2C_SR2_BUSY);       /* wait until bus not busy */
	I2C1->CR1 |= I2C_CR1_START;             /* generate start */
	while (!(I2C1->SR1 & I2C_SR1_SB));      /* wait until start flag is set */
	I2C1->DR = (uint8_t)saddr << 1;         /* transmit slave address + Write */
	while (!(I2C1->SR1 & I2C_SR1_ADDR));    /* wait until addr flag is set */
	tmp = I2C1->SR1;              			/* clear addr flag */
	tmp = I2C1->SR2;
	while (!(I2C1->SR1 & I2C_SR1_TXE));   	/* wait until data register empty */
	I2C1->DR = maddr;               		/* send memory address */
	while (!(I2C1->SR1 & I2C_SR1_TXE));    	/* wait until data register empty */
	I2C1->CR1 |= 0x100;             		/* generate restart */
	while (!(I2C1->SR1 & I2C_SR1_SB));      /* wait until start flag is set */
	I2C1->DR = (uint8_t)(saddr << 1 | 0x01);/* transmit slave address + Read */
	while (!(I2C1->SR1 & I2C_SR1_ADDR));    /* wait until addr flag is set */
	I2C1->CR1 &= ~I2C_CR1_ACK;            	/* Disable Acknowledge */
	tmp = I2C1->SR1;                		/* clear addr flag */
	tmp = I2C1->SR2;                		/* clear addr flag */
	while (!(I2C1->SR1 & I2C_SR1_RXNE));    /* Wait until RXNE flag is set */
	I2C1->CR1 |= I2C_CR1_STOP;            	/* generate stop after data received */
	*data++ = (uint8_t)I2C1->DR;            /* Read data from DR */
	return 0;
}

// it works!
// https://github.com/ENG-EDISON/STM32_I2C1_I2C2_USART2_MPU6050_BareMetal
int I2C1_byteWrite(char saddr, char maddr, uint8_t* data)
{
	volatile uint8_t tmp = 0;
	while (I2C1->SR2 & I2C_SR2_BUSY);       /* wait until bus not busy */
	I2C1->CR1 |= 0x100; 					/* generate start */
	while (!(I2C1->SR1 & 1));               /* wait until start flag is set */
	I2C1->DR = saddr << 1;                  /* transmit slave address */
	while(!(I2C1->SR1 & 2));                /* wait until addr flag is set */
	tmp = I2C1->SR2;                        /* clear addr flag */
	while (!(I2C1->SR1 & 0x80));            /* wait until data register empty */
	I2C1->DR = maddr;                       /* send memory address */
	while (!(I2C1->SR1 & 0x80));            /* wait until data register empty */
	I2C1->DR = *data;                       /* transmit data */
	while (!(I2C1->SR1 & 4));               /* wait until transfer finished */
	I2C1->CR1 |= 0x200;                     /* generate stop */
	return 0;
}

int I2C1_burstRead(char saddr, char maddr, int n, uint8_t* data)
{
	volatile uint32_t tmp = 0;
	while (I2C1->SR2 & I2C_SR2_BUSY);       /* wait until bus not busy */
	I2C1->CR1 |= I2C_CR1_START;             /* generate start */
	while (!(I2C1->SR1 & I2C_SR1_SB));      /* wait until start flag is set */
	I2C1->DR = (uint8_t)saddr << 1;         /* transmit slave address + Write */
	while (!(I2C1->SR1 & I2C_SR1_ADDR));    /* wait until addr flag is set */
	tmp = I2C1->SR1;              			/* clear addr flag */
	tmp = I2C1->SR2;
	while (!(I2C1->SR1 & I2C_SR1_TXE));   	/* wait until data register empty */
	I2C1->DR = maddr;               		/* send memory address */
	while (!(I2C1->SR1 & I2C_SR1_TXE));    	/* wait until data register empty */
	I2C1->CR1 |= 0x100;             		/* generate restart */
	while (!(I2C1->SR1 & I2C_SR1_SB));      /* wait until start flag is set */
	I2C1->DR = (uint8_t)(saddr << 1 | 0x01);/* transmit slave address + Read */
	while (!(I2C1->SR1 & I2C_SR1_ADDR));    /* wait until addr flag is set */
	tmp = I2C1->SR1;                		/* clear addr flag */
	tmp = I2C1->SR2;                		/* clear addr flag */
	I2C1->CR1 |= I2C_CR1_ACK;            	/* Enable Acknowledge */
	while (n > 0U)
	{
    	if (n == 1U)
    	{
    		I2C1->CR1 &= ~I2C_CR1_ACK;            	/* Disable Acknowledge */
    		tmp = I2C1->SR1;                		/* clear addr flag */
    		tmp = I2C1->SR2;                		/* clear addr flag */
    		while (!(I2C1->SR1 & I2C_SR1_RXNE));    /* Wait until RXNE flag is set */
    		I2C1->CR1 |= I2C_CR1_STOP;            	/* generate stop after data received */
    		*data++ = (uint8_t)I2C1->DR;            /* Read data from DR */
    		break;
    	}
    	else
    	{
    		while (!(I2C1->SR1 & I2C_SR1_RXNE));    /* Wait until RXNE flag is set */
    		*data++ = (uint8_t)I2C1->DR;            /* Read data from DR */
    		--n;
    	}
	}
	return 0;
}

int I2C1_burstWrite(char saddr, char maddr, int n, uint8_t* data)
{
	volatile uint8_t tmp = 0;
	while (I2C1->SR2 & I2C_SR2_BUSY);       /* wait until bus not busy */
	I2C1->CR1 |= 0x100; 					/* generate start */
	while (!(I2C1->SR1 & 1));               /* wait until start flag is set */
	I2C1->DR = saddr << 1;                  /* transmit slave address */
	while(!(I2C1->SR1 & 2));                /* wait until addr flag is set */
	tmp = I2C1->SR2;                        /*clear addr flag */
	while (!(I2C1->SR1 & 0x80));            /* wait until data register empty */
	I2C1->DR = maddr;                       /* send memory address */
    for (int i = 0; i < n; i++)
    {
    	while (!(I2C1->SR1 & 0x80));        /* wait until data register empty */
    	I2C1->DR = *data++;                 /* transmit data */
    }
	while (!(I2C1->SR1 & 4));               /* wait until transfer finished */
	I2C1->CR1 |= 0x200;                     /* generate stop */
	return 0;
}

void SPI1_transmit(uint8_t *data, uint32_t size)
{
    uint32_t i = 0;
    volatile uint8_t temp;

    while (i < size)
    {
        while (!(SPI1->SR & (SPI_SR_TXE))) {}   /* Wait until TXE is set */
        SPI1->DR = data[i];                 /* Write the data to the data register */
        i++;
    }
    while (!(SPI1->SR & (SPI_SR_TXE))) {}       /* Wait until TXE is set */
    while ((SPI1->SR & (SPI_SR_BSY))) {}        /* Wait for BUSY flag to reset */
    temp = SPI1->DR;                        /* Clear OVR flag */
    temp = SPI1->SR;
}

void SPI1_receive(uint8_t *data, uint32_t size)
{
    while (size)
    {
        SPI1->DR = 0;                       /* Send dummy data */
        while (!(SPI1->SR & (SPI_SR_RXNE))) {}  /* Wait for RXNE flag to be set */
        *data++ = (SPI1->DR);               /* Read data from data register */
        size--;
    }
}

/* USER CODE END 4 */

void Error_Handler(void)
{
  __disable_irq();
  while (1)
  {
  }
}
